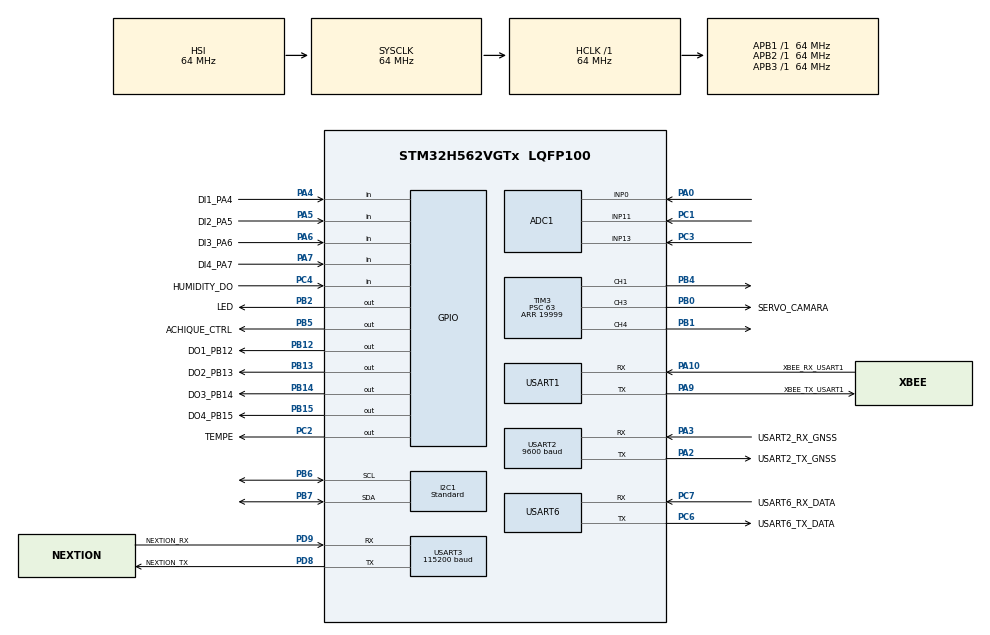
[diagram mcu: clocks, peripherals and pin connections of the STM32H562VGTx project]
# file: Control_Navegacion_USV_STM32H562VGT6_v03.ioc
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ADC1.Channel-0\#ChannelRegularConversion=ADC_CHANNEL_0
ADC1.Channel-1\#ChannelRegularConversion=ADC_CHANNEL_11
ADC1.Channel-2\#ChannelRegularConversion=ADC_CHANNEL_13
ADC1.ContinuousConvMode=ENABLE
ADC1.ConversionDataManagement=ADC_CONVERSIONDATA_DMA_CIRCULAR
ADC1.DMAContinuousRequests=ENABLE
ADC1.MonitoredBy-0\#ChannelRegularConversion=__NULL
ADC1.MonitoredBy-1\#ChannelRegularConversion=__NULL
ADC1.MonitoredBy-2\#ChannelRegularConversion=__NULL
ADC1.NbrOfConversion=3
ADC1.NbrOfConversionFlag=1
ADC1.OffsetNumber-0\#ChannelRegularConversion=ADC_OFFSET_NONE
ADC1.OffsetNumber-1\#ChannelRegularConversion=ADC_OFFSET_NONE
ADC1.OffsetNumber-2\#ChannelRegularConversion=ADC_OFFSET_NONE
ADC1.Rank-0\#ChannelRegularConversion=1
ADC1.Rank-1\#ChannelRegularConversion=2
ADC1.Rank-2\#ChannelRegularConversion=3
ADC1.SamplingTime-0\#ChannelRegularConversion=ADC_SAMPLETIME_47CYCLES_5
ADC1.SamplingTime-1\#ChannelRegularConversion=ADC_SAMPLETIME_47CYCLES_5
ADC1.SamplingTime-2\#ChannelRegularConversion=ADC_SAMPLETIME_47CYCLES_5
ADC1.master=1
BOOTPATH.BootPathName=LEGACY
BOOTPATH.UserSelectedBootPath=LEGACY
CORTEX_M33_NS.Number-Cortex_Memory_Protection_Unit_Region0_OTP_RO_AREAS_Settings=MPU_REGION_NUMBER0
CORTEX_M33_NS.default_mode_Activation=1
CORTEX_M33_NS.userName=CORTEX_M33
GPDMA1.CIRCULARMODE_GPDMACH0=DISABLE
GPDMA1.CIRCULARMODE_GPDMACH1=ENABLE
GPDMA1.DESTDATAWIDTH_GPDMACH1=DMA_DEST_DATAWIDTH_HALFWORD
GPDMA1.DESTINC_GPDMACH0=DMA_DINC_INCREMENTED
GPDMA1.DESTINC_GPDMACH1=DMA_DINC_INCREMENTED
GPDMA1.DESTINC_GPDMACH2=DMA_DINC_INCREMENTED
GPDMA1.IPHANDLE_GPDMACH0-SIMPLEREQUEST_GPDMACH0=__NULL
GPDMA1.IPHANDLE_GPDMACH1-SIMPLEREQUEST_GPDMACH1=__NULL
GPDMA1.IPHANDLE_GPDMACH2-SIMPLEREQUEST_GPDMACH2=__NULL
GPDMA1.PRIORITY_GPDMACH0=DMA_LOW_PRIORITY_MID_WEIGHT
GPDMA1.REQUEST_GPDMACH0=GPDMA1_REQUEST_USART1_RX
GPDMA1.REQUEST_GPDMACH1=GPDMA1_REQUEST_ADC1
GPDMA1.REQUEST_GPDMACH2=GPDMA1_REQUEST_USART2_RX
GPDMA1.SRCDATAWIDTH_GPDMACH1=DMA_SRC_DATAWIDTH_HALFWORD
GPDMA1.SRCINC_GPDMACH1=DMA_SINC_FIXED
I2C1.I2C_Speed_Mode=I2C_Standard
I2C1.Timing=0x30924056
Mcu.Family=STM32H5
Mcu.Name=STM32H562VGTx
Mcu.Package=LQFP100
NVIC.GPDMA1_Channel0_IRQn=true\:0\:0\:false\:false\:true\:false\:true\:true
NVIC.GPDMA1_Channel2_IRQn=true\:0\:0\:false\:false\:true\:true\:true\:true
NVIC.PriorityGroup=NVIC_PRIORITYGROUP_4
NVIC.USART1_IRQn=true\:0\:0\:false\:false\:true\:true\:true\:true
NVIC.USART2_IRQn=true\:0\:0\:false\:false\:true\:true\:true\:true
NVIC.USART3_IRQn=true\:0\:0\:false\:false\:true\:true\:true\:true
NVIC.USART6_IRQn=true\:0\:0\:false\:false\:true\:true\:true\:true
PA0.Signal=ADCx_INP0
PA10.GPIO_Label=XBEE_RX_USART1
PA10.Mode=Asynchronous
PA10.Signal=USART1_RX
PA13(JTMS/SWDIO).Mode=Serial_Wire
PA13(JTMS/SWDIO).Signal=DEBUG_JTMS-SWDIO
PA14(JTCK/SWCLK).Mode=Serial_Wire
PA14(JTCK/SWCLK).Signal=DEBUG_JTCK-SWCLK
PA2.GPIO_Label=USART2_TX_GNSS
PA2.Mode=Asynchronous
PA2.Signal=USART2_TX
PA3.GPIO_Label=USART2_RX_GNSS
PA3.Mode=Asynchronous
PA3.Signal=USART2_RX
PA4.GPIO_Label=DI1_PA4
PA4.GPIO_Mode=GPIO_MODE_INPUT
PA4.GPIO_PuPd=GPIO_NOPULL
PA4.Signal=GPIO_Input
PA5.GPIO_Label=DI2_PA5
PA5.Signal=GPIO_Input
PA6.GPIO_Label=DI3_PA6
PA6.Signal=GPIO_Input
PA7.GPIO_Label=DI4_PA7
PA7.Signal=GPIO_Input
PA9.GPIO_Label=XBEE_TX_USART1
PA9.Mode=Asynchronous
PA9.Signal=USART1_TX
PB0.GPIO_Label=SERVO_CAMARA
PB0.Signal=S_TIM3_CH3
PB1.Signal=S_TIM3_CH4
PB12.GPIO_Label=DO1_PB12
PB12.Signal=GPIO_Output
PB13.GPIO_Label=DO2_PB13
PB13.Signal=GPIO_Output
PB14.GPIO_Label=DO3_PB14
PB14.Signal=GPIO_Output
PB15.GPIO_Label=DO4_PB15
PB15.Signal=GPIO_Output
PB2.GPIO_Label=LED
PB2.Signal=GPIO_Output
PB4(NJTRST).Signal=S_TIM3_CH1
PB5.GPIO_Label=ACHIQUE_CTRL
PB5.GPIO_ModeDefaultOutputPP=GPIO_MODE_OUTPUT_OD
PB5.GPIO_PuPd=GPIO_NOPULL
PB5.PinState=GPIO_PIN_SET
PB5.Signal=GPIO_Output
PB6.GPIO_PuPd=GPIO_PULLUP
PB6.Mode=I2C
PB6.Signal=I2C1_SCL
PB7.GPIO_PuPd=GPIO_PULLUP
PB7.Mode=I2C
PB7.Signal=I2C1_SDA
PC1.Signal=ADCx_INP11
PC2.GPIO_Label=TEMPE
PC2.GPIO_ModeDefaultOutputPP=GPIO_MODE_OUTPUT_OD
PC2.GPIO_PuPd=GPIO_NOPULL
PC2.PinState=GPIO_PIN_SET
PC2.Signal=GPIO_Output
PC3.Signal=ADCx_INP13
PC4.GPIO_Label=HUMIDITY_DO
PC4.Signal=GPIO_Input
PC6.GPIO_Label=USART6_TX_DATA
PC6.Mode=Asynchronous
PC6.Signal=USART6_TX
PC7.GPIO_Label=USART6_RX_DATA
PC7.Mode=Asynchronous
PC7.Signal=USART6_RX
PD8.GPIO_Label=NEXTION_TX
PD8.Mode=Asynchronous
PD8.Signal=USART3_TX
PD9.GPIO_Label=NEXTION_RX
PD9.Mode=Asynchronous
PD9.Signal=USART3_RX
ProjectManager.HeapSize=0x200
ProjectManager.StackSize=0x400
ProjectManager.TargetToolchain=CMake
RCC.ADCFreq_Value=64000000
RCC.AHBFreq_Value=64000000
RCC.APB1Freq_Value=64000000
RCC.APB1TimFreq_Value=64000000
RCC.APB2Freq_Value=64000000
RCC.APB2TimFreq_Value=64000000
RCC.APB3Freq_Value=64000000
RCC.CSI_VALUE=4000000
RCC.CortexFreq_Value=64000000
RCC.EPOD_VALUE=4000000
RCC.HCLKFreq_Value=64000000
RCC.HSE_VALUE=25000000
RCC.HSI48_VALUE=48000000
RCC.HSIDiv=RCC_HSI_DIV1
RCC.HSI_VALUE=64000000
RCC.LSE_VALUE=32768
RCC.LSIRC_VALUE=32000
RCC.SYSCLKFreq_VALUE=64000000
RCC.USBFreq_Value=48000000
RCC.VCOOutputFreq_Value=516000000
SH.ADCx_INP0.0=ADC1_INP0,IN0-Single-Ended
SH.ADCx_INP11.0=ADC1_INP11,IN11-Single-Ended
SH.ADCx_INP13.0=ADC1_INP13,IN13-Single-Ended
SH.S_TIM3_CH1.0=TIM3_CH1,PWM Generation1 CH1
SH.S_TIM3_CH3.0=TIM3_CH3,PWM Generation3 CH3
SH.S_TIM3_CH4.0=TIM3_CH4,PWM Generation4 CH4
TIM3.Channel-PWM\ Generation1\ CH1=TIM_CHANNEL_1
TIM3.Channel-PWM\ Generation3\ CH3=TIM_CHANNEL_3
TIM3.Channel-PWM\ Generation4\ CH4=TIM_CHANNEL_4
TIM3.PeriodNoDither=19999
TIM3.Prescaler=63
TIM3.PulseNoDither_3=1500
USART1.VirtualMode-Asynchronous=VM_ASYNC
USART2.BaudRate=9600
USART2.VirtualMode-Asynchronous=VM_ASYNC
USART3.BaudRate=115200
USART3.VirtualMode-Asynchronous=VM_ASYNC
USART6.VirtualMode=VM_ASYNC
VP_BOOTPATH_VS_BOOTPATH.Mode=BP_Activate
VP_CORTEX_M33_NS_VS_Hclk.Mode=Hclk_Mode
VP_GPDMA1_VS_GPDMACH0.Mode=SIMPLEREQUEST_GPDMACH0
VP_GPDMA1_VS_GPDMACH1.Mode=SIMPLEREQUEST_GPDMACH1
VP_GPDMA1_VS_GPDMACH2.Mode=SIMPLEREQUEST_GPDMACH2
VP_ICACHE_VS_ICACHE.Mode=DirectMappedCache
VP_MEMORYMAP_VS_MEMORYMAP.Mode=CurAppReg
VP_PWR_VS_LPOM.Mode=PowerOptimisation
VP_PWR_VS_SECSignals.Mode=Security/Privilege
VP_TIM3_VS_ClockSourceINT.Mode=Internal
board=custom

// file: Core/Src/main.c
/* USER CODE BEGIN Header */
/**
  ******************************************************************************
  * @file           : main.c
  * @brief          : Main program body
  ******************************************************************************
  * @attention
  *
  * Copyright (c) 2026 STMicroelectronics.
  * All rights reserved.
  *
  * This software is licensed under terms that can be found in the LICENSE file
  * in the root directory of this software component.
  * If no LICENSE file comes with this software, it is provided AS-IS.
  *
  ******************************************************************************
  */
/* USER CODE END Header */
#include "main.h"

/* USER CODE BEGIN Includes */

#include "servos.h"
#include "UARTRX.h"
#include <stdio.h>
#include "imu_bno085_i2c.h"
#include "TELEMETRIA_USV.h"
#include "trama_usv.h"
#include <math.h>
#include "stm32h5xx_hal_gpio.h"
#include "string.h"
#include "stdlib.h"
#include "uart.h"

#include "gps.h"
#include "adc_x.h"
#include "temp_ds18b20.h"
#include "usv_motores.h"
#include "pcb_banco.h"
#include "corriente_lem.h"

#include "stdio.h"
#include "stdlib.h"
#include "stdint.h"

/* USER CODE END Includes */

/* USER CODE BEGIN PD */

/*
 * PRUEBA 12.1:
 * La estacion puede ordenar y aplicar el rango completo -100..+100 %.
 * Se mantienen parada de emergencia y failsafe de enlace a 500 ms.
 */
#define USV_PRUEBA_MOTOR_LIMITE_PCT   100
#define USV_FAILSAFE_TIERRA_MS         500U
/* Tiempo inicial, ajustar con mediciones y perfiles reales XCTU. */
#define XBEE_REPLY_GUARD_MS             60U
/* Rearme RX solamente; no prolongar el failsafe de la propulsion. */
#define XBEE_RX_REARME_SILENCIO_MS     3000U
#define XBEE_RX_REARME_INTERVALO_MS   1000U

/* USER CODE END PD */

ADC_HandleTypeDef hadc1;
DMA_NodeTypeDef Node_GPDMA1_Channel1;
DMA_QListTypeDef List_GPDMA1_Channel1;
DMA_HandleTypeDef handle_GPDMA1_Channel1;

I2C_HandleTypeDef hi2c1;

TIM_HandleTypeDef htim3;

UART_HandleTypeDef huart1;
UART_HandleTypeDef huart2;
UART_HandleTypeDef huart3;
UART_HandleTypeDef huart6;
DMA_HandleTypeDef handle_GPDMA1_Channel0;
DMA_HandleTypeDef handle_GPDMA1_Channel2;

/* USER CODE BEGIN PV */
extern volatile uint32_t usv_xbee_uart1_error_irq;
extern volatile uint32_t usv_xbee_uart1_error_codigo;
extern volatile uint8_t usv_xbee_uart1_recuperar;
char texto[600];

volatile uint8_t imu_ok = 0U;
volatile uint8_t imu_addr = 0U;
volatile uint8_t imu_data_ok = 0U;
/* Diagnostico de arranque inmutable: se muestra en Teleplot a 2 Hz. */
static IMU_Diagnostico imu_diag_arranque;
/* USV 14.9: diagnostico de espera inicial, solo en el arranque. */
#define IMU_149_ESPERA_MS 1500U
static uint32_t imu_149_tick_antes_espera = 0U;
static uint32_t imu_149_tick_inicio = 0U;
static uint32_t imu_149_tick_fin = 0U;
static uint32_t imu_149_espera_real_ms = 0U;
static uint32_t imu_149_init_duracion_ms = 0U;

/* USV 15.0: resultado de sondeo directo unico, previo a IMU_Init.
 * estado: 0=no consultado, 1=STOP sin NACK (ACK probable),
 * 2=NACK observado, 3=espera agotada, 4=error de bus, 5=bus no libre.
 * isr_eventos conserva los bits detectados antes de limpiar banderas.
 */
typedef struct
{
    uint8_t estado;
    uint32_t isr_eventos;
    uint32_t isr_fin;
    uint32_t duracion_ms;
} USV_IMU150_Probe;
static USV_IMU150_Probe imu_150_4a;
static USV_IMU150_Probe imu_150_4b;
static uint32_t imu_150_pe_inicial = 0U;
static uint8_t imu_150_bus_seguro = 0U;

/* USV 15.1: fotografia de registros GPIOB justo antes de consultar la IMU.
 * Se almacenan en RAM; ninguna escritura a GPIOB ni a I2C1.
 */
typedef struct
{
    uint32_t tick_ms;
    uint32_t moder;
    uint32_t otyper;
    uint32_t ospeedr;
    uint32_t pupdr;
    uint32_t afrl;
    uint32_t idr;
} USV_IMU151_GPIO;
static USV_IMU151_GPIO imu_151_gpio;

/* USV 15.2: captura del reloj y TIMINGR efectivo antes de consultar BNO085.
 * Bus estandar 100 kHz nominal: PCLK1=64 MHz, tr=300 ns, tf=100 ns,
 * filtro analogico habilitado, filtro digital 0.
 * Valor calculado estimado; frecuencia fisica depende del bus real.
 */
#define USV_I2C1_TIMING_100KHZ 0x30924056U
static uint32_t imu_152_pclk1_hz = 0U;
static uint32_t imu_152_timingr = 0U;

/* USV 15.4: escaneo exhaustivo de las 112 direcciones I2C de 7 bits
 * que no estan reservadas (0x08 a 0x77 inclusive).
 * El sondeo se hace UNA SOLA VEZ antes de IMU_Init() y se lee desde RAM.
 * Estado: 0=no ejecutado, 1=en curso, 2=completado, 3=interrumpido.
 */
#define USV_I2C_SCAN_MIN_ADDR 0x08U
#define USV_I2C_SCAN_MAX_ADDR 0x77U
#define USV_I2C_SCAN_TOTAL (USV_I2C_SCAN_MAX_ADDR - USV_I2C_SCAN_MIN_ADDR + 1U)
typedef struct
{
    uint8_t estado;
    uint8_t ultimo_addr;
    uint8_t total_ack;
    uint8_t ack_addr[USV_I2C_SCAN_TOTAL];
    uint8_t hal_4a; /* 255=no consultada; 0=HAL_OK */
    uint8_t hal_4b;
    uint16_t consultadas;
    uint16_t hal_error;
    uint16_t hal_timeout;
    uint16_t hal_busy;
    uint16_t error_bus;
    uint32_t err_4a;
    uint32_t err_4b;
    uint32_t pclk1_hz;
    uint32_t timingr;
    uint32_t duracion_ms;
    uint32_t mascara_ack[4]; /* bit N: direccion N (0-127) */
} USV_I2C_ScanResultado;
static USV_I2C_ScanResultado i2c_scan_154;
static uint8_t i2c_scan_154_indice_publicar = 0U;

float imu_roll = 0.0f;
float imu_pitch = 0.0f;
float imu_yaw = 0.0f;

uint32_t imu_last_ms = 0U;
uint32_t teleplot_last_ms = 0U;

/* Heartbeat del lazo principal: incrementa una vez por segundo. */
uint32_t main_alive_last_ms = 0U;
uint32_t main_alive = 0U;

uint32_t temperatura_last_ms = 0U;
uint32_t temperatura_conversion_inicio_ms = 0U;
uint8_t temperatura_conversion_activa = 0U;
float temperatura_c = -100.0f;
uint8_t gps_rmc_ok = 0U;
uint8_t gps_gga_ok = 0U;
uint32_t gnss_rx_eventos = 0U;
uint32_t gnss_ultimo_fix_ms = 0U;
uint32_t servo_test_last_ms = 0U;
uint8_t servo_test_estado = 0U;
float servo_test_angulo = 0.0f;
uint16_t motor_babor_pwm_us = PWM_NEUTRO;
uint16_t motor_estribor_pwm_us = PWM_NEUTRO;
uint8_t motores_pwm_activos = 0U;
uint32_t motores_test_last_ms = 0U;
uint8_t motores_test_estado = 0U;

/* Prueba local de bomba de achique por PB5 / ACHIQUE_CTRL. */
uint32_t bomba_test_last_ms = 0U;
uint8_t bomba_test_estado = 0U;

uint16_t corriente_adc_raw = 0U;
float corriente_voltaje_v = 0.0f;
float corriente_lem_a = 0.0f;

uint16_t bateria_adc_raw = 0U;
float bateria_adc_v = 0.0f;
float bateria_voltaje_v = 0.0f;

/* Ultima trama $PUSVU decodificada desde USART1 / estacion de tierra. */
USV_Comando comando_tierra;
uint8_t comando_tierra_valido = 0U;
static uint8_t xbee_fragmento_rx[600U];
static char xbee_linea[USV_TRAMA_MAXIMA];
static uint16_t xbee_linea_n = 0U;
static uint32_t xbee_tramas_descartadas = 0U;
static uint32_t xbee_rx_eventos = 0U;
static uint32_t xbee_rx_bytes = 0U;
static uint32_t xbee_rx_ultimo_evento_ms = 0U;
static uint32_t xbee_rx_ultimo_rearme_ms = 0U;
static uint32_t xbee_rx_rearmes_ok = 0U;
static uint32_t xbee_rx_rearmes_error = 0U;
static uint32_t xbee_rx_watchdog = 0U;
static uint8_t xbee_reply_pendiente = 0U;
static uint32_t xbee_reply_deadline_ms = 0U;

/* Estado de control remoto para la prueba 12.0. */
int16_t cmd_babor_rx_pct = 0;
int16_t cmd_estribor_rx_pct = 0;
int16_t cmd_camara_rx_deg = 0;
int16_t motor_babor_aplicado_pct = 0;
int16_t motor_estribor_aplicado_pct = 0;
uint8_t parada_rx = 0U;
uint8_t enlace_tierra_ok = 0U;
uint8_t failsafe_tierra_activo = 1U;
uint32_t comando_tierra_ultimo_valido_ms = 0U;
uint32_t pusvu_rx_validas = 0U;

/* Diagnostico desacoplado de la recepcion para no bloquear USART1. */
uint32_t pusvu_diag_last_ms = 0U;
uint8_t pusvu_diag_pendiente = 0U;
uint8_t pusvu_diag_ultimo_valido = 0U;

char teleplot_tx[240];
uint8_t imu_raw[23];

int16_t imu_qi_raw = 0;
int16_t imu_qj_raw = 0;
int16_t imu_qk_raw = 0;
int16_t imu_qr_raw = 0;

volatile uint8_t imu_raw_ok = 0U;
volatile uint8_t imu_raw_channel = 0U;
volatile uint8_t imu_raw_report = 0U;
volatile uint16_t imu_raw_length = 0U;

/*
 * Diagnostico visual del enlace ESTACION -> BOTE.
 *
 * Mientras lleguen tramas por USART1, PB2 conmuta cada 250 ms.
 * Si pasan mas de 400 ms sin recibir nada, se detiene el parpadeo.
 */
uint32_t led_rx_ultimo_evento_ms = 0U;
uint32_t led_rx_ultimo_toggle_ms = 0U;
uint8_t led_rx_activo = 0U;
/* USER CODE END PV */

void SystemClock_Config(void);
static void MPU_Config(void);
static void MX_GPIO_Init(void);
static void MX_GPDMA1_Init(void);
static void MX_ICACHE_Init(void);
static void MX_USART1_UART_Init(void);
static void MX_USART2_UART_Init(void);
static void MX_USART6_UART_Init(void);
static void MX_I2C1_Init(void);
static void MX_TIM3_Init(void);
static void MX_USART3_UART_Init(void);
static void MX_ADC1_Init(void);
/* USER CODE BEGIN PFP */
void procesa_rx(void);
/* USER CODE END PFP */

/* USER CODE BEGIN 0 */
/* DMA+IDLE no representa trama completa: acumular fragmentos hasta CRLF. */
static uint8_t XBee_ExtraerComandos(
        const uint8_t *bytes, uint16_t cantidad,
        USV_Comando *comando, uint8_t *linea_completa)
{
    uint8_t correcto = 0U;
    uint16_t i;
    if ((bytes == NULL) || (comando == NULL) || (linea_completa == NULL))
        return 0U;
    *linea_completa = 0U;
    for (i = 0U; i < cantidad; ++i)
    {
        uint8_t c = bytes[i];
        if (c == (uint8_t)'$')
            xbee_linea_n = 0U;
        else if (xbee_linea_n == 0U)
            continue;
        if (xbee_linea_n >= USV_TRAMA_MAXIMA - 1U)
        {
            ++xbee_tramas_descartadas;
            xbee_linea_n = 0U;
            continue;
        }
        xbee_linea[xbee_linea_n++] = (char)c;
        if (c == (uint8_t)'\n')
        {
            USV_Comando actual;
            xbee_linea[xbee_linea_n] = '\0';
            *linea_completa = 1U;
            if (USV_LeerComando(xbee_linea, &actual) != 0U)
            {
                *comando = actual;
                correcto = 1U;
            }
            else
                ++xbee_tramas_descartadas;
            xbee_linea_n = 0U;
        }
    }
    return correcto;
}

/* Convierte coordenadas decimales entregadas por gps.c al formato NMEA
 * ddmm.mmmm / dddmm.mmmm esperado por Trama Version 3. */
static void USV_GNSS_FormatearCoord(double decimal, uint8_t lon,
                                   char *destino, size_t capacidad)
{
    double abs_coord = (decimal < 0.0) ? -decimal : decimal;
    unsigned long grados = (unsigned long)abs_coord;
    double minutos = (abs_coord - (double)grados) * 60.0;
    if (minutos >= 59.99995)
    {
        ++grados;
        minutos = 0.0;
    }
    if (lon != 0U)
        (void)snprintf(destino, capacidad, "%03lu%07.4f", grados, minutos);
    else
        (void)snprintf(destino, capacidad, "%02lu%07.4f", grados, minutos);
}

/* Sincroniza la estructura de telemetria con las mediciones GNSS decodificadas.
 * NO cambia la velocidad y el rumbo si aun no hay solucion valida. */
static void USV_ActualizarTelemetriaGNSS(uint8_t fix_valido)
{
    char utc[USV_TAMANO_UTC];
    char lat_nmea[USV_TAMANO_COORDENADA];
    char lon_nmea[USV_TAMANO_COORDENADA];
    uint16_t hdop10, vel10, rumbo10;
    int32_t alt10;
    uint8_t calidad, sats;
    uint8_t hh = (uint8_t)(((int16_t)hor_gps + 5 + 24) % 24);

    if (fix_valido == 0U)
    {
        TELEMETRIA1.datos.calidad_gps = 0U;
        TELEMETRIA1.datos.satelites = 0U;
        return;
    }
    /* gps.c ofrece hora LOCAL de Colombia; convertir de nuevo a UTC. */
    (void)snprintf(utc, sizeof(utc), "%02u%02u%02u.00",
                   (unsigned)hh, (unsigned)min_gps, (unsigned)seg_gps);
    USV_GNSS_FormatearCoord(latitud, 0U, lat_nmea, sizeof(lat_nmea));
    USV_GNSS_FormatearCoord(longitud, 1U, lon_nmea, sizeof(lon_nmea));
    calidad = (uint8_t)((gps_modo >= 1 && gps_modo <= 8) ?
                         gps_modo : 1);
    sats = (uint8_t)((gps_satelites >= 0 && gps_satelites <= 24) ?
                     gps_satelites : 0);
    hdop10 = (uint16_t)((gps_hor_dilu >= 0.5f &&
                         gps_hor_dilu <= 50.0f) ?
                        (gps_hor_dilu * 10.0f + 0.5f) : 500.0f);
    alt10 = (int32_t)((gps_altura >= -10.0f &&
                       gps_altura <= 9999.0f) ?
                       (gps_altura * 10.0f) : 0.0f);
    /* La Trama V3 etiqueta velocidad con N: transmitir NUDOS, no km/h. */
    vel10 = (uint16_t)((gps_vel_nudos >= 0.0f &&
                        gps_vel_nudos <= 30.0f) ?
                        (gps_vel_nudos * 10.0f + 0.5f) : 0.0f);
    rumbo10 = (uint16_t)((gps_rumbo >= 0.0f &&
                          gps_rumbo < 360.0f) ?
                         (gps_rumbo * 10.0f + 0.5f) : 0.0f);
    TELEMETRIA_USV_GPS(&TELEMETRIA1, utc, lat_nmea,
                       (latitud < 0.0) ? 'S' : 'N',
                       lon_nmea, (longitud < 0.0) ? 'W' : 'E',
                       calidad, sats, hdop10, alt10, vel10, rumbo10);
}

/*
 * Convierte los angulos reales del BNO085 al formato exigido por $PUSVD.
 *
 * - yaw:   0.0 ... 359.9 grados, almacenado x10.
 * - pitch: -90.0 ... +90.0 grados, almacenado x10.
 * - roll:  -90.0 ... +90.0 grados, almacenado x10.
 *
 * El BNO085 puede entregar roll fuera de +/-90 dependiendo de la orientacion.
 * La Trama Version 3 no admite ese rango, por eso se satura antes de enviarlo.
 */
static void USV_ActualizarTelemetriaIMU(
        float roll,
        float pitch,
        float yaw)
{
    int32_t yaw_x10;
    int32_t pitch_x10;
    int32_t roll_x10;

    while (yaw < 0.0f)
    {
        yaw += 360.0f;
    }

    while (yaw >= 360.0f)
    {
        yaw -= 360.0f;
    }

    if (pitch < -90.0f)
    {
        pitch = -90.0f;
    }
    else if (pitch > 90.0f)
    {
        pitch = 90.0f;
    }

    if (roll < -90.0f)
    {
        roll = -90.0f;
    }
    else if (roll > 90.0f)
    {
        roll = 90.0f;
    }

    yaw_x10 =
        (int32_t)((yaw * 10.0f) + 0.5f);

    pitch_x10 =
        (int32_t)((pitch >= 0.0f) ?
            ((pitch * 10.0f) + 0.5f) :
            ((pitch * 10.0f) - 0.5f));

    roll_x10 =
        (int32_t)((roll >= 0.0f) ?
            ((roll * 10.0f) + 0.5f) :
            ((roll * 10.0f) - 0.5f));

    if (yaw_x10 > 3599)
    {
        yaw_x10 = 3599;
    }

    TELEMETRIA_USV_IMU(
        &TELEMETRIA1,
        (uint16_t)yaw_x10,
        (int16_t)pitch_x10,
        (int16_t)roll_x10);
}

/*
 * Reconstruye el porcentaje con signo desde la estructura decodificada.
 * Positivo = avante, negativo = reversa.
 */
static int16_t USV_ComandoMotorFirmado(
        uint16_t potencia,
        uint8_t avante,
        uint8_t atras)
{
    if ((avante != 0U) && (atras == 0U))
    {
        return (int16_t)potencia;
    }

    if ((avante == 0U) && (atras != 0U))
    {
        return -(int16_t)potencia;
    }

    return 0;
}

/*
 * Limita el porcentaje de prueba y lo convierte a PWM ESC:
 * -100 % = 1000 us, 0 % = 1500 us, +100 % = 2000 us.
 * Para la prueba 12.1 se habilita el rango completo +/-100 %.
 */
static uint16_t USV_MotorPctAPwmPrueba(
        int16_t porcentaje,
        int16_t *porcentaje_aplicado)
{
    int16_t limitado = porcentaje;
    int32_t pwm;

    if (limitado > USV_PRUEBA_MOTOR_LIMITE_PCT)
    {
        limitado = USV_PRUEBA_MOTOR_LIMITE_PCT;
    }
    else if (limitado < -USV_PRUEBA_MOTOR_LIMITE_PCT)
    {
        limitado = -USV_PRUEBA_MOTOR_LIMITE_PCT;
    }

    if (porcentaje_aplicado != NULL)
    {
        *porcentaje_aplicado = limitado;
    }

    pwm = (int32_t)PWM_NEUTRO + ((int32_t)limitado * 5);

    if (pwm > PWM_MAX_ADELANTE)
    {
        pwm = PWM_MAX_ADELANTE;
    }
    else if (pwm < PWM_MAX_REVERSA)
    {
        pwm = PWM_MAX_REVERSA;
    }

    return (uint16_t)pwm;
}

/* void procesa_rx()
 {
  char procesa[100];
    char texto[100];
if (strstr(UARTRX1.trama_rx,"$PUSVU"))
	    {
	        strcpy(procesa, strtok(UARTRX1.trama_rx, "$"));  //inicia captura de tokens desde el =
	        strcpy(procesa, strtok(0, ","));  //captura hasta el /
strcpy(procesa, strtok(0, ","));  //captura hasta el /
strcpy(procesa, strtok(0, ","));  //captura hasta el /
strcpy(procesa, strtok(0, ","));  //captura hasta el /
strcpy(procesa, strtok(0, ","));  //captura hasta el /
strcpy(procesa, strtok(0, ","));  //captura hasta el /
 float serv=atof(procesa); // con signo
 sprintf(texto, "Servo= %.2f\r\n\r\n", serv);
 uartx_write_text(&huart1, texto);

 }
  } */
/* USV 15.0: prueba I2C de direccion (NBYTES=0) sin usar HAL en paralelo.
 * Solo puede ejecutarse con HAL READY y el bus inactivo, en arranque.
 * No se modifica la configuracion TIMINGR ni los GPIO.
 * Limite de 15 ms por direccion. No reintenta ni se invoca en while(1).
 */
static uint8_t USV_IMU150_ProbarDireccion(uint8_t direccion7,
                                         USV_IMU150_Probe *resultado)
{
    uint32_t tick_inicio;
    uint32_t isr;
    uint32_t cr2_previo;

    if (resultado == NULL)
    {
        return 0U;
    }
    memset(resultado, 0, sizeof(*resultado));
    if ((HAL_I2C_GetState(&hi2c1) != HAL_I2C_STATE_READY) ||
        ((hi2c1.Instance->CR1 & I2C_CR1_PE) == 0U) ||
        ((hi2c1.Instance->ISR & I2C_ISR_BUSY) != 0U))
    {
        resultado->estado = 5U;
        resultado->isr_fin = hi2c1.Instance->ISR;
        return 0U;
    }

    cr2_previo = hi2c1.Instance->CR2;
    /* Borrar exclusivamente banderas residuales de la prueba anterior. */
    hi2c1.Instance->ICR = I2C_ICR_NACKCF | I2C_ICR_STOPCF |
                          I2C_ICR_BERRCF | I2C_ICR_ARLOCF;
    tick_inicio = HAL_GetTick();
    /* Direccion SADD de 7 bits desplazada; AUTOEND con NBYTES=0. */
    hi2c1.Instance->CR2 = ((uint32_t)direccion7 << 1U) |
                          I2C_CR2_AUTOEND | I2C_CR2_START;

    do
    {
        isr = hi2c1.Instance->ISR;
        resultado->isr_eventos |= isr & (I2C_ISR_NACKF |
            I2C_ISR_STOPF | I2C_ISR_BERR | I2C_ISR_ARLO);
        if ((isr & (I2C_ISR_BERR | I2C_ISR_ARLO)) != 0U)
        {
            resultado->estado = 4U;
            break;
        }
        if ((isr & I2C_ISR_STOPF) != 0U)
        {
            resultado->estado =
                ((resultado->isr_eventos & I2C_ISR_NACKF) != 0U) ? 2U : 1U;
            break;
        }
    } while ((uint32_t)(HAL_GetTick() - tick_inicio) < 15U);

    if (resultado->estado == 0U)
    {
        resultado->estado = 3U;
    }
    resultado->duracion_ms = HAL_GetTick() - tick_inicio;
    resultado->isr_fin = hi2c1.Instance->ISR;

    if ((resultado->isr_fin & I2C_ISR_BUSY) != 0U)
    {
        /* No escribir CR2 ni iniciar nuevas transacciones con BUSY activo. */
        resultado->estado = 5U;
        return 0U;
    }
    hi2c1.Instance->ICR = I2C_ICR_NACKCF | I2C_ICR_STOPCF |
                          I2C_ICR_BERRCF | I2C_ICR_ARLOCF;
    hi2c1.Instance->CR2 = cr2_previo;
    /* Solo encadenar transacciones si se observo STOP completo. */
    return (resultado->estado == 1U || resultado->estado == 2U) ? 1U : 0U;
}

/* USV 15.4: escaneo de direcciones, sin escritura de datos.
 * HAL_I2C_IsDeviceReady emite la direccion 7-bit desplazada.
 * Cada direccion se consulta una sola vez, con limite de 10 ms.
 * Si hay bloqueo/BUSY/error de bus, se declara incompleto.
 */
static void USV_I2C_ScanCompleto(void)
{
    uint8_t addr;
    uint32_t inicio = HAL_GetTick();
    HAL_StatusTypeDef estado_hal;
    uint32_t error;

    memset(&i2c_scan_154, 0, sizeof(i2c_scan_154));
    i2c_scan_154.hal_4a = 255U;
    i2c_scan_154.hal_4b = 255U;
    i2c_scan_154.pclk1_hz = HAL_RCC_GetPCLK1Freq();
    i2c_scan_154.timingr = hi2c1.Instance->TIMINGR;

    if ((HAL_I2C_GetState(&hi2c1) != HAL_I2C_STATE_READY) ||
        ((hi2c1.Instance->CR1 & I2C_CR1_PE) == 0U) ||
        ((hi2c1.Instance->ISR & I2C_ISR_BUSY) != 0U))
    {
        i2c_scan_154.estado = 3U;
        i2c_scan_154.hal_busy = 1U;
        i2c_scan_154.duracion_ms = HAL_GetTick() - inicio;
        return;
    }

    i2c_scan_154.estado = 1U;
    for (addr = USV_I2C_SCAN_MIN_ADDR; addr <= USV_I2C_SCAN_MAX_ADDR; ++addr)
    {
        estado_hal = HAL_I2C_IsDeviceReady(
            &hi2c1, (uint16_t)((uint16_t)addr << 1U), 1U, 10U);
        error = HAL_I2C_GetError(&hi2c1);

        i2c_scan_154.consultadas++;
        i2c_scan_154.ultimo_addr = addr;

        if (addr == 0x4AU)
        {
            i2c_scan_154.hal_4a = (uint8_t)estado_hal;
            i2c_scan_154.err_4a = error;
        }
        if (addr == 0x4BU)
        {
            i2c_scan_154.hal_4b = (uint8_t)estado_hal;
            i2c_scan_154.err_4b = error;
        }

        if (estado_hal == HAL_OK)
        {
            i2c_scan_154.ack_addr[i2c_scan_154.total_ack++] = addr;
            i2c_scan_154.mascara_ack[addr / 32U] |=
                (1UL << (addr % 32U));
        }
        else if (estado_hal == HAL_ERROR)
        {
            i2c_scan_154.hal_error++;
        }
        else if (estado_hal == HAL_TIMEOUT)
        {
            i2c_scan_154.hal_timeout++;
            i2c_scan_154.estado = 3U;
            break;
        }
        else /* HAL_BUSY */
        {
            i2c_scan_154.hal_busy++;
            i2c_scan_154.estado = 3U;
            break;
        }

        if ((error & (HAL_I2C_ERROR_BERR | HAL_I2C_ERROR_ARLO)) != 0U)
        {
            i2c_scan_154.error_bus++;
            i2c_scan_154.estado = 3U;
            break;
        }
        if ((hi2c1.Instance->ISR & I2C_ISR_BUSY) != 0U)
        {
            i2c_scan_154.hal_busy++;
            i2c_scan_154.estado = 3U;
            break;
        }
    }

    if (i2c_scan_154.consultadas == USV_I2C_SCAN_TOTAL &&
        i2c_scan_154.estado == 1U)
    {
        i2c_scan_154.estado = 2U;
    }
    i2c_scan_154.duracion_ms = HAL_GetTick() - inicio;
}

/* USER CODE END 0 */

int main(void)
{

  /* MCU Configuration--------------------------------------------------------*/

  /* MPU Configuration--------------------------------------------------------*/
  MPU_Config();

  /* Reset of all peripherals, Initializes the Flash interface and the Systick. */
  HAL_Init();

  /* Configure the system clock */
  SystemClock_Config();

  /* Initialize all configured peripherals */
  MX_GPIO_Init();
  MX_GPDMA1_Init();
  MX_ICACHE_Init();
  MX_USART1_UART_Init();
  MX_USART2_UART_Init();
  MX_USART6_UART_Init();
  MX_I2C1_Init();
  MX_TIM3_Init();
  MX_USART3_UART_Init();
  MX_ADC1_Init();
  /* USER CODE BEGIN 2 */

/*
 * AUTOPRUEBA PB2:
 * Al arrancar, el LED cambia de estado durante 300 ms y vuelve al estado inicial.
 * Si este destello no se ve, el problema esta en PB2/LED y no en la UART.
 */
HAL_GPIO_WritePin(
    LED_RX_TIERRA_GPIO_Port,
    LED_RX_TIERRA_Pin,
    GPIO_PIN_SET);
HAL_Delay(300U);

HAL_GPIO_WritePin(
    LED_RX_TIERRA_GPIO_Port,
    LED_RX_TIERRA_Pin,
    GPIO_PIN_RESET);
HAL_Delay(300U);

// Inicializa la señal PWM en el pin PB0 (SERVO_CAMARA)
#if !PCB_BANCO_ACTIVO
SERVO_init(&SERVO1);
SERVO_ANG(&SERVO1, 0.0f);
#else
/* En banco, no generar PWM del servo hasta recibir orden manual. */
servo_test_angulo = 0.0f;
#endif // Posiciona inicialmente la cámara al centro (0°)

/*
 * PRUEBA LOCAL MOTORES 6.2:
 * Inicia únicamente las salidas PWM de propulsion en NEUTRO.
 * No se ejecuta USV_Motor_Calibrar() y no se ordena movimiento.
 * Babor    = PB4 / TIM3_CH1
 * Estribor = PB1 / TIM3_CH4
 */
if ((HAL_TIM_PWM_Start(&htim3, TIM_CHANNEL_1) == HAL_OK) &&
    (HAL_TIM_PWM_Start(&htim3, TIM_CHANNEL_4) == HAL_OK))
{
    USV_Motor_Set(&htim3, TIM_CHANNEL_1, PWM_NEUTRO);
    USV_Motor_Set(&htim3, TIM_CHANNEL_4, PWM_NEUTRO);

    motor_babor_pwm_us = PWM_NEUTRO;
    motor_estribor_pwm_us = PWM_NEUTRO;
    motores_pwm_activos = 1U;
}

/*
 * La prueba de bomba inicia con el rele desenergizado.
 * PB5 es open-drain y el rele es activo en LOW:
 * SET = alta impedancia = OFF.
 * RESET = 0 V = ON.
 */
HAL_GPIO_WritePin(
    ACHIQUE_CTRL_GPIO_Port,
    ACHIQUE_CTRL_Pin,
    GPIO_PIN_SET);
bomba_test_estado = 0U;
bomba_test_last_ms = HAL_GetTick();

uartx_write_text(&huart6, "INICIANDO\r\n");
#if PCB_BANCO_ACTIVO
PCB_Banco_Iniciar();
#endif
//uartRX_it_idle_dma_init(&UARTRX1);
uartRX_it_idle_dma_init(&GPS_UARTRX);   // USART1 / estacion de tierra
xbee_rx_ultimo_evento_ms = HAL_GetTick();
xbee_rx_ultimo_rearme_ms = HAL_GetTick();
uartRX_it_idle_dma_init(&GNSS_UARTRX);   // USART2 / GPS L76K

// Inicializa la telemetria oficial $PUSVD por USART1 / XBee
TELEMETRIA_USV_init(&TELEMETRIA1);

/* USV 14.9: espera adicional fija para probar estabilidad de arranque.
 * Las dos pausas existentes de 300 ms del LED permanecen intactas.
 * No se modifican I2C1, XBee, PWM, SHTP ni el failsafe.
 * Atencion: esta espera bloquea el avance de la secuencia de arranque.
 */
imu_149_tick_antes_espera = HAL_GetTick();
HAL_Delay(IMU_149_ESPERA_MS);
imu_149_tick_inicio = HAL_GetTick();
imu_149_espera_real_ms = imu_149_tick_inicio - imu_149_tick_antes_espera;

/* USV 15.4: escanear antes de hacer comprobaciones del BNO085.
 * No reconfigura PB6/PB7 ni modifica el protocolo de los subsistemas.
 */
USV_I2C_ScanCompleto();

/* USV 15.2: capturar reloj PCLK1 y TIMINGR cargado en I2C1. */
imu_152_pclk1_hz = HAL_RCC_GetPCLK1Freq();
imu_152_timingr = hi2c1.Instance->TIMINGR;

/* USV 15.1: leer GPIOB justo antes de la primera consulta I2C.
 * PB6 = SCL y PB7 = SDA. Esta lectura no cambia el hardware.
 */
imu_151_gpio.tick_ms = HAL_GetTick();
imu_151_gpio.moder = GPIOB->MODER;
imu_151_gpio.otyper = GPIOB->OTYPER;
imu_151_gpio.ospeedr = GPIOB->OSPEEDR;
imu_151_gpio.pupdr = GPIOB->PUPDR;
imu_151_gpio.afrl = GPIOB->AFR[0];
imu_151_gpio.idr = GPIOB->IDR;

/* USV 15.0: dos sondeos directos antes de HAL_I2C_IsDeviceReady.
 * Si 0x4A no libera bus, omitir 0x4B y conservar el diagnostico.
 */
imu_150_pe_inicial = (hi2c1.Instance->CR1 & I2C_CR1_PE) != 0U;
if (USV_IMU150_ProbarDireccion(0x4AU, &imu_150_4a) != 0U)
{
    imu_150_bus_seguro = USV_IMU150_ProbarDireccion(0x4BU, &imu_150_4b);
}

// Evitar HAL si algun sondeo no concluyo con STOP completo.
if ((imu_150_bus_seguro != 0U) &&
    ((hi2c1.Instance->ISR & I2C_ISR_BUSY) == 0U))
{
    imu_ok = IMU_Init();
}
else
{
    imu_ok = 0U;
}
imu_149_tick_fin = HAL_GetTick();
imu_149_init_duracion_ms = imu_149_tick_fin - imu_149_tick_inicio;
imu_addr = IMU_GetAddress7bit();
IMU_GetDiagnostico(&imu_diag_arranque);

// Inicializa DS18B20 / 1-Wire en PC2 (TEMPE)
TEMPE_Init();

/*
 * Inicia ADC1 por DMA usando la libreria adc_x.
 * CubeMX tiene 3 conversiones:
 * [0] PA0, [1] PC1, [2] PC3 (humedad).
 * PC2 ya no pertenece al ADC: se usa para DS18B20 / 1-Wire.
 * Se pasa 3 de forma explicita para no modificar la libreria adc_x.
 */
ADC_Read_DMA(&hadc1, 3U, adc1_codigo);

  /* USER CODE END 2 */

  /* Infinite loop */
  /* USER CODE BEGIN WHILE */
  while (1)
  {
#if PCB_BANCO_ACTIVO
    PCB_Banco_Tarea();
#endif
    /*
     * Heartbeat de diagnostico.
     * Si main_alive sigue aumentando, el while(1) continua ejecutandose.
     */
    if ((uint32_t)(HAL_GetTick() - main_alive_last_ms) >= 1000U)
    {
        main_alive_last_ms = HAL_GetTick();
        main_alive++;
    }

    /* Lectura IMU cada 50 ms */
    if ((HAL_GetTick() - imu_last_ms) >= 50U)
    {
        imu_last_ms = HAL_GetTick();

        if (IMU_ReadEuler(
                &imu_roll,
                &imu_pitch,
                &imu_yaw) != 0U)
        {
            imu_data_ok = 1U;

            USV_ActualizarTelemetriaIMU(
                imu_roll,
                imu_pitch,
                imu_yaw);
        }
    }

    /*
     * PRUEBA 12.0:
     * Servo y motores ya no se fuerzan aqui a una posicion fija.
     * Las salidas se actualizan exclusivamente cuando llega una $PUSVU
     * valida y por el failsafe de perdida de enlace definido mas abajo.
     */

    /* La bomba arranca desenergizada y solo cambia por una orden
     * PUSVU valida o cuando el failsafe corta el enlace. */

    /*
     * TEMPERATURA DS18B20 NO BLOQUEANTE:
     *
     * La conversion se inicia cada 2 s y el main continua ejecutandose.
     * Transcurridos 750 ms se lee el scratchpad. De esta forma USART1,
     * Teleplot, IMU y el resto de tareas siguen siendo atendidos durante
     * el tiempo de conversion del sensor.
     */
    {
        uint32_t ahora_temp = HAL_GetTick();

        if (temperatura_conversion_activa == 0U)
        {
            if ((uint32_t)(ahora_temp - temperatura_last_ms) >= 2000U)
            {
                temperatura_last_ms = ahora_temp;

                if (TEMPE_StartConversion() != 0U)
                {
                    temperatura_conversion_inicio_ms = ahora_temp;
                    temperatura_conversion_activa = 1U;
                }
                else
                {
                    temperatura_c = -100.0f;
                }
            }
        }
        else if ((uint32_t)(ahora_temp - temperatura_conversion_inicio_ms) >= 750U)
        {
            temperatura_c = TEMPE_ReadResult();
            temperatura_conversion_activa = 0U;
            /* No inventar temperatura cuando el DS18B20 no responde.
             * La version 3 admite -10.0..85.0 C. */
            if ((temperatura_c >= -10.0f) && (temperatura_c <= 85.0f))
            {
                TELEMETRIA1.datos.temperatura_x10 =
                    (int16_t)((temperatura_c * 10.0f) +
                        ((temperatura_c >= 0.0f) ? 0.5f : -0.5f));
            }
        }
    }

    /*
     * TELEPLOT SEGURO 11.4:
     * Se limita a 2 Hz para reducir la carga de USART6 durante la prueba
     * continua de comunicacion con la estacion de tierra.
     */
    if ((HAL_GetTick() - teleplot_last_ms) >= 500U)
    {
        float humedad_pct;
        int len;

        teleplot_last_ms = HAL_GetTick();

        /*
         * SENSOR DE CORRIENTE LEM HASS 200-S:
         * PA0 = ADC1_INP0 = adc1_codigo[0].
         * Se conserva intacta la libreria corriente_lem.
         */
        corriente_adc_raw = adc1_codigo[0];
        corriente_voltaje_v =
            ((float)corriente_adc_raw / STM32_ADC_MAX_CODES) *
            STM32_ADC_VREF;
        corriente_lem_a =
            LEM_HASS200_ObtenerCorriente(corriente_adc_raw);

        /*
         * SENSOR DE VOLTAJE DE BATERIA:
         * PC1 = ADC1_INP11 = adc1_codigo[1].
         * Divisor nominal: R1=20 kOhm, R2=4.7 kOhm.
         * Factor nominal = (20k + 4.7k) / 4.7k = 5.255.
         *
         * Para esta primera prueba se usa el factor nominal y se compara
         * contra el multimetro antes de aplicar cualquier calibracion.
         */
        bateria_adc_raw = adc1_codigo[1];
        bateria_adc_v =
            ((float)bateria_adc_raw / 4095.0f) * 3.3f;
        bateria_voltaje_v =
            bateria_adc_v * 5.255f;

        /*
         * INTEGRACION $PUSVD 9.1:
         * Convierte las mediciones electricas al formato x10 de la trama.
         * Se preservan temperatura e inundacion hasta integrarlas en su etapa.
         */
        {
            float bateria_tx_v = bateria_voltaje_v;
            float corriente_tx_a = corriente_lem_a;
            uint16_t bateria_tx_x10;
            uint16_t corriente_tx_x10;

            if (bateria_tx_v < 0.0f)
            {
                bateria_tx_v = 0.0f;
            }
            else if (bateria_tx_v > 14.0f)
            {
                bateria_tx_v = 14.0f;
            }

            if (corriente_tx_a < 0.0f)
            {
                corriente_tx_a = 0.0f;
            }
            else if (corriente_tx_a > 100.0f)
            {
                corriente_tx_a = 100.0f;
            }

            bateria_tx_x10 =
                (uint16_t)((bateria_tx_v * 10.0f) + 0.5f);

            corriente_tx_x10 =
                (uint16_t)((corriente_tx_a * 10.0f) + 0.5f);

            TELEMETRIA_USV_SENSORES(
                &TELEMETRIA1,
                TELEMETRIA1.datos.temperatura_x10,
                TELEMETRIA1.datos.inundacion,
                bateria_tx_x10,
                corriente_tx_x10);
        }

        humedad_pct =
            ((4095.0f - (float)adc1_codigo[2]) * 100.0f) /
            (4095.0f - 1466.0f);

        if (humedad_pct < 0.0f)
        {
            humedad_pct = 0.0f;
        }
        else if (humedad_pct > 100.0f)
        {
            humedad_pct = 100.0f;
        }

        /* Bloque 1: sensores basicos y servo. */
        len = snprintf(
            texto,
            sizeof(texto),
            ">humedad_adc:%u\r\n"
            ">humedad_pct:%.1f\r\n"
            ">temperatura_c:%.2f\r\n"
            ">servo_angulo:%.1f\r\n"
            ">servo_pwm_us:%lu\r\n"
            ">cmd_babor_rx_pct:%d\r\n"
            ">cmd_estribor_rx_pct:%d\r\n"
            ">cmd_camara_rx_deg:%d\r\n"
            ">motor_babor_aplicado_pct:%d\r\n"
            ">motor_estribor_aplicado_pct:%d\r\n"
            ">motores_pwm_activos:%u\r\n"
            ">motor_babor_pwm_us:%u\r\n"
            ">motor_estribor_pwm_us:%u\r\n"
            ">parada_rx:%u\r\n"
            ">enlace_tierra_ok:%u\r\n"
            ">failsafe_tierra:%u\r\n"
            ">pusvu_rx_validas:%lu\r\n"
            ">bomba_achique:%u\r\n"
            ">main_alive:%lu\r\n",
            (unsigned int)adc1_codigo[2],
            humedad_pct,
            temperatura_c,
            servo_test_angulo,
            (unsigned long)TIM3->CCR3,
            (int)cmd_babor_rx_pct,
            (int)cmd_estribor_rx_pct,
            (int)cmd_camara_rx_deg,
            (int)motor_babor_aplicado_pct,
            (int)motor_estribor_aplicado_pct,
            (unsigned int)motores_pwm_activos,
            (unsigned int)motor_babor_pwm_us,
            (unsigned int)motor_estribor_pwm_us,
            (unsigned int)parada_rx,
            (unsigned int)enlace_tierra_ok,
            (unsigned int)failsafe_tierra_activo,
            (unsigned long)pusvu_rx_validas,
            (unsigned int)bomba_test_estado,
            (unsigned long)main_alive);

        if ((len > 0) && ((size_t)len < sizeof(texto)))
        {
            uartx_write_text(&huart6, texto);
        }

        /* Bloque 2: diagnostico IMU. */
        len = snprintf(
            texto,
            sizeof(texto),
            ">imu_ok:%u\r\n"
            ">imu_addr:%u\r\n"
            ">imu_data_ok:%u\r\n"
            ">imu_i2c_pines:%u\r\n"
            ">imu_i2c_error_hal:%lu\r\n"
            ">imu_diag_etapa:%u\r\n"
            ">imu_probe_4a_hal:%u\r\n"
            ">imu_probe_4a_error:%lu\r\n"
            ">imu_probe_4b_hal:%u\r\n"
            ">imu_probe_4b_error:%lu\r\n"
            ">imu_diag_error_etapa:%lu\r\n"
            ">roll:%.2f\r\n"
            ">pitch:%.2f\r\n"
            ">yaw:%.2f\r\n",
            (unsigned int)imu_ok,
            (unsigned int)imu_addr,
            (unsigned int)imu_data_ok,
            (unsigned int)((GPIOB->IDR >> 6U) & 0x3U),
            (unsigned long)HAL_I2C_GetError(&hi2c1),
            (unsigned int)imu_diag_arranque.etapa,
            (unsigned int)imu_diag_arranque.estado_4a,
            (unsigned long)imu_diag_arranque.error_4a,
            (unsigned int)imu_diag_arranque.estado_4b,
            (unsigned long)imu_diag_arranque.error_4b,
            (unsigned long)imu_diag_arranque.error_etapa,
            imu_roll,
            imu_pitch,
            imu_yaw);

        if ((len > 0) && ((size_t)len < sizeof(texto)))
        {
            uartx_write_text(&huart6, texto);
        }

        /* USV 14.7: instantaneas I2C1 de arranque; lectura de RAM a 2 Hz. */
        len = snprintf(
            texto, sizeof(texto),
            ">imu_i2c_estado:%lu\r\n"
            ">imu_i2c_modo:%lu\r\n"
            ">imu_i2c_isr:%lu\r\n"
            ">imu_i2c_busy:%u\r\n"
            ">imu_i2c_nack:%u\r\n"
            ">imu_i2c_berr:%u\r\n"
            ">imu_i2c_arbitration:%u\r\n"
            ">imu_i2c_isr_inicial:%lu\r\n"
            ">imu_i2c_isr_4a:%lu\r\n"
            ">imu_i2c_isr_4b:%lu\r\n",
            (unsigned long)imu_diag_arranque.estado_i2c,
            (unsigned long)imu_diag_arranque.modo_i2c,
            (unsigned long)imu_diag_arranque.isr_final,
            (unsigned int)((imu_diag_arranque.isr_final & I2C_ISR_BUSY) != 0U),
            (unsigned int)((imu_diag_arranque.isr_final & I2C_ISR_NACKF) != 0U),
            (unsigned int)((imu_diag_arranque.isr_final & I2C_ISR_BERR) != 0U),
            (unsigned int)((imu_diag_arranque.isr_final & I2C_ISR_ARLO) != 0U),
            (unsigned long)imu_diag_arranque.isr_inicial,
            (unsigned long)imu_diag_arranque.isr_4a,
            (unsigned long)imu_diag_arranque.isr_4b);
        if ((len > 0) && ((size_t)len < sizeof(texto)))
        {
            uartx_write_text(&huart6, texto);
        }

        /* USV 14.8: traza de pruebas HAL 0x4A y 0x4B; solo RAM. */
        len = snprintf(
            texto, sizeof(texto),
            ">imu_148_cr1:%lu\r\n"
            ">imu_148_cr2:%lu\r\n"
            ">imu_148_timingr:%lu\r\n"
            ">imu_148_pe:%u\r\n"
            ">imu_148_addrmode:%lu\r\n"
            ">imu_148_4a_s1:%u\r\n"
            ">imu_148_4a_s2:%u\r\n"
            ">imu_148_4a_s3:%u\r\n"
            ">imu_148_4b_s1:%u\r\n"
            ">imu_148_4b_s2:%u\r\n"
            ">imu_148_4b_s3:%u\r\n",
            (unsigned long)imu_diag_arranque.cr1_inicio,
            (unsigned long)imu_diag_arranque.cr2_inicio,
            (unsigned long)imu_diag_arranque.timingr_inicio,
            (unsigned int)((imu_diag_arranque.cr1_inicio & I2C_CR1_PE) != 0U),
            (unsigned long)imu_diag_arranque.addressing_mode,
            (unsigned int)imu_diag_arranque.probe_hal[0][0],
            (unsigned int)imu_diag_arranque.probe_hal[0][1],
            (unsigned int)imu_diag_arranque.probe_hal[0][2],
            (unsigned int)imu_diag_arranque.probe_hal[1][0],
            (unsigned int)imu_diag_arranque.probe_hal[1][1],
            (unsigned int)imu_diag_arranque.probe_hal[1][2]);
        if ((len > 0) && ((size_t)len < sizeof(texto)))
        {
            uartx_write_text(&huart6, texto);
        }
        len = snprintf(
            texto, sizeof(texto),
            ">imu_148_4a_e1:%lu\r\n"
            ">imu_148_4a_e2:%lu\r\n"
            ">imu_148_4a_e3:%lu\r\n"
            ">imu_148_4b_e1:%lu\r\n"
            ">imu_148_4b_e2:%lu\r\n"
            ">imu_148_4b_e3:%lu\r\n"
            ">imu_148_4a_t1:%lu\r\n"
            ">imu_148_4a_t2:%lu\r\n"
            ">imu_148_4a_t3:%lu\r\n"
            ">imu_148_4b_t1:%lu\r\n"
            ">imu_148_4b_t2:%lu\r\n"
            ">imu_148_4b_t3:%lu\r\n",
            (unsigned long)imu_diag_arranque.probe_error[0][0],
            (unsigned long)imu_diag_arranque.probe_error[0][1],
            (unsigned long)imu_diag_arranque.probe_error[0][2],
            (unsigned long)imu_diag_arranque.probe_error[1][0],
            (unsigned long)imu_diag_arranque.probe_error[1][1],
            (unsigned long)imu_diag_arranque.probe_error[1][2],
            (unsigned long)imu_diag_arranque.probe_duracion_ms[0][0],
            (unsigned long)imu_diag_arranque.probe_duracion_ms[0][1],
            (unsigned long)imu_diag_arranque.probe_duracion_ms[0][2],
            (unsigned long)imu_diag_arranque.probe_duracion_ms[1][0],
            (unsigned long)imu_diag_arranque.probe_duracion_ms[1][1],
            (unsigned long)imu_diag_arranque.probe_duracion_ms[1][2]);
        if ((len > 0) && ((size_t)len < sizeof(texto)))
        {
            uartx_write_text(&huart6, texto);
        }

        /* USV 14.9: tiempos de arranque IMU, leidos desde RAM. */
        len = snprintf(
            texto, sizeof(texto),
            ">imu_149_espera_config_ms:%lu\r\n"
            ">imu_149_tick_antes_espera:%lu\r\n"
            ">imu_149_tick_inicio:%lu\r\n"
            ">imu_149_tick_fin:%lu\r\n"
            ">imu_149_espera_real_ms:%lu\r\n"
            ">imu_149_init_duracion_ms:%lu\r\n",
            (unsigned long)IMU_149_ESPERA_MS,
            (unsigned long)imu_149_tick_antes_espera,
            (unsigned long)imu_149_tick_inicio,
            (unsigned long)imu_149_tick_fin,
            (unsigned long)imu_149_espera_real_ms,
            (unsigned long)imu_149_init_duracion_ms);
        if ((len > 0) && ((size_t)len < sizeof(texto)))
        {
            uartx_write_text(&huart6, texto);
        }

        /* USV 15.0: instantaneas tomadas antes de que HAL limpie NACKF. */
        len = snprintf(
            texto, sizeof(texto),
            ">imu_150_pe:%lu\r\n"
            ">imu_150_bus_seguro:%u\r\n"
            ">imu_150_4a_estado:%u\r\n"
            ">imu_150_4a_eventos:%lu\r\n"
            ">imu_150_4a_isr_fin:%lu\r\n"
            ">imu_150_4a_tiempo_ms:%lu\r\n"
            ">imu_150_4b_estado:%u\r\n"
            ">imu_150_4b_eventos:%lu\r\n"
            ">imu_150_4b_isr_fin:%lu\r\n"
            ">imu_150_4b_tiempo_ms:%lu\r\n",
            (unsigned long)imu_150_pe_inicial,
            (unsigned int)imu_150_bus_seguro,
            (unsigned int)imu_150_4a.estado,
            (unsigned long)imu_150_4a.isr_eventos,
            (unsigned long)imu_150_4a.isr_fin,
            (unsigned long)imu_150_4a.duracion_ms,
            (unsigned int)imu_150_4b.estado,
            (unsigned long)imu_150_4b.isr_eventos,
            (unsigned long)imu_150_4b.isr_fin,
            (unsigned long)imu_150_4b.duracion_ms);
        if ((len > 0) && ((size_t)len < sizeof(texto)))
        {
            uartx_write_text(&huart6, texto);
        }

        /* USV 15.1: registros GPIOB capturados antes de probar la IMU. */
        len = snprintf(
            texto, sizeof(texto),
            ">imu_151_tick_ms:%lu\r\n"
            ">imu_151_moder:%lu\r\n"
            ">imu_151_otyper:%lu\r\n"
            ">imu_151_ospeedr:%lu\r\n"
            ">imu_151_pupdr:%lu\r\n"
            ">imu_151_afrl:%lu\r\n"
            ">imu_151_idr:%lu\r\n",
            (unsigned long)imu_151_gpio.tick_ms,
            (unsigned long)imu_151_gpio.moder,
            (unsigned long)imu_151_gpio.otyper,
            (unsigned long)imu_151_gpio.ospeedr,
            (unsigned long)imu_151_gpio.pupdr,
            (unsigned long)imu_151_gpio.afrl,
            (unsigned long)imu_151_gpio.idr);
        if ((len > 0) && ((size_t)len < sizeof(texto)))
        {
            uartx_write_text(&huart6, texto);
        }

        /* Interpretacion individual de los pines PB6 / PB7 desde RAM:
         * MODER=2 (alternativa), OTYPER=1 (open drain),
         * PUPDR=1 (pull up), AFRL=4 (I2C1).
         * LEVEL 1=alto en la instantanea, no demuestra ACK.
         */
        len = snprintf(
            texto, sizeof(texto),
            ">imu_151_pb6_mode:%lu\r\n"
            ">imu_151_pb7_mode:%lu\r\n"
            ">imu_151_pb6_od:%lu\r\n"
            ">imu_151_pb7_od:%lu\r\n"
            ">imu_151_pb6_pull:%lu\r\n"
            ">imu_151_pb7_pull:%lu\r\n"
            ">imu_151_pb6_af:%lu\r\n"
            ">imu_151_pb7_af:%lu\r\n"
            ">imu_151_pb6_level:%lu\r\n"
            ">imu_151_pb7_level:%lu\r\n",
            (unsigned long)((imu_151_gpio.moder >> 12U) & 0x3U),
            (unsigned long)((imu_151_gpio.moder >> 14U) & 0x3U),
            (unsigned long)((imu_151_gpio.otyper >> 6U) & 0x1U),
            (unsigned long)((imu_151_gpio.otyper >> 7U) & 0x1U),
            (unsigned long)((imu_151_gpio.pupdr >> 12U) & 0x3U),
            (unsigned long)((imu_151_gpio.pupdr >> 14U) & 0x3U),
            (unsigned long)((imu_151_gpio.afrl >> 24U) & 0xFU),
            (unsigned long)((imu_151_gpio.afrl >> 28U) & 0xFU),
            (unsigned long)((imu_151_gpio.idr >> 6U) & 0x1U),
            (unsigned long)((imu_151_gpio.idr >> 7U) & 0x1U));
        if ((len > 0) && ((size_t)len < sizeof(texto)))
        {
            uartx_write_text(&huart6, texto);
        }

        /* USV 15.2: reloj y temporizacion efectivos, sin sondeos extra. */
        len = snprintf(
            texto, sizeof(texto),
            ">imu_152_pclk1_hz:%lu\r\n"
            ">imu_152_timingr:%lu\r\n"
            ">imu_152_timing_ok:%u\r\n"
            ">imu_152_pclk_ok:%u\r\n",
            (unsigned long)imu_152_pclk1_hz,
            (unsigned long)imu_152_timingr,
            (unsigned int)(imu_152_timingr == USV_I2C1_TIMING_100KHZ),
            (unsigned int)(imu_152_pclk1_hz == 64000000U));
        if ((len > 0) && ((size_t)len < sizeof(texto)))
        {
            uartx_write_text(&huart6, texto);
        }

        /* USV 15.4: publica resultado del escaneo desde RAM, a 2 Hz.
         * estado=2 y consultadas=112 prueban que el barrido fue completo.
         * Las mascaras contienen todos los ACK; no se omiten dispositivos.
         */
        len = snprintf(
            texto, sizeof(texto),
            ">i2c_scan_estado:%u\r\n"
            ">i2c_scan_completo:%u\r\n"
            ">i2c_scan_consultadas:%u\r\n"
            ">i2c_scan_total:%u\r\n"
            ">i2c_scan_ultimo_addr:%u\r\n"
            ">i2c_scan_encontrados:%u\r\n"
            ">i2c_scan_hal_error:%u\r\n"
            ">i2c_scan_hal_timeout:%u\r\n"
            ">i2c_scan_hal_busy:%u\r\n"
            ">i2c_scan_error_bus:%u\r\n"
            ">i2c_scan_4a_hal:%u\r\n"
            ">i2c_scan_4a_error:%lu\r\n"
            ">i2c_scan_4b_hal:%u\r\n"
            ">i2c_scan_4b_error:%lu\r\n"
            ">i2c_scan_pclk1_hz:%lu\r\n"
            ">i2c_scan_timingr:%lu\r\n"
            ">i2c_scan_duracion_ms:%lu\r\n",
            (unsigned int)i2c_scan_154.estado,
            (unsigned int)(i2c_scan_154.estado == 2U),
            (unsigned int)i2c_scan_154.consultadas,
            (unsigned int)USV_I2C_SCAN_TOTAL,
            (unsigned int)i2c_scan_154.ultimo_addr,
            (unsigned int)i2c_scan_154.total_ack,
            (unsigned int)i2c_scan_154.hal_error,
            (unsigned int)i2c_scan_154.hal_timeout,
            (unsigned int)i2c_scan_154.hal_busy,
            (unsigned int)i2c_scan_154.error_bus,
            (unsigned int)i2c_scan_154.hal_4a,
            (unsigned long)i2c_scan_154.err_4a,
            (unsigned int)i2c_scan_154.hal_4b,
            (unsigned long)i2c_scan_154.err_4b,
            (unsigned long)i2c_scan_154.pclk1_hz,
            (unsigned long)i2c_scan_154.timingr,
            (unsigned long)i2c_scan_154.duracion_ms);
        if ((len > 0) && ((size_t)len < sizeof(texto)))
        {
            uartx_write_text(&huart6, texto);
        }
        /* Lista explicita de TODOS los ACK, hasta 16 por ciclo Teleplot.
         * Si hay mas, se rotan los restantes entre ciclos.
         * El nombre incluye la direccion hexadecimal: i2c_ack_4A=1.
         */
        if (i2c_scan_154.total_ack > 0U)
        {
            uint8_t n;
            for (n = 0U; n < 16U && n < i2c_scan_154.total_ack; ++n)
            {
                uint8_t addr_encontrada =
                    i2c_scan_154.ack_addr[i2c_scan_154_indice_publicar];
                len = snprintf(texto, sizeof(texto),
                    ">i2c_ack_%02X:1\r\n", (unsigned int)addr_encontrada);
                if ((len > 0) && ((size_t)len < sizeof(texto)))
                {
                    uartx_write_text(&huart6, texto);
                }
                i2c_scan_154_indice_publicar++;
                if (i2c_scan_154_indice_publicar >= i2c_scan_154.total_ack)
                {
                    i2c_scan_154_indice_publicar = 0U;
                }
            }
        }
        /* Mascaras de 32 direcciones: bit N = ACK en direccion N.
         * Permiten reconstruir el barrido completo sin enviar 112 etiquetas.
         */
        len = snprintf(
            texto, sizeof(texto),
            ">i2c_scan_mask_00_1f:%lu\r\n"
            ">i2c_scan_mask_20_3f:%lu\r\n"
            ">i2c_scan_mask_40_5f:%lu\r\n"
            ">i2c_scan_mask_60_7f:%lu\r\n",
            (unsigned long)i2c_scan_154.mascara_ack[0],
            (unsigned long)i2c_scan_154.mascara_ack[1],
            (unsigned long)i2c_scan_154.mascara_ack[2],
            (unsigned long)i2c_scan_154.mascara_ack[3]);
        if ((len > 0) && ((size_t)len < sizeof(texto)))
        {
            uartx_write_text(&huart6, texto);
        }

        /* Bloque 3: estado de recepcion GNSS. */
        len = snprintf(
            texto,
            sizeof(texto),
            ">gnss_rx_eventos:%lu\r\n"
            ">gnss_rx_bytes:%u\r\n"
            ">gps_rmc_ok:%u\r\n"
            ">gps_gga_ok:%u\r\n"
            ">gps_fix:%d\r\n"
            ">gps_satelites:%d\r\n"
            ">gps_hdop:%.2f\r\n",
            (unsigned long)gnss_rx_eventos,
            (unsigned int)GNSS_UARTRX.num_datos,
            (unsigned int)gps_rmc_ok,
            (unsigned int)gps_gga_ok,
            (int)gps_modo,
            (int)gps_satelites,
            gps_hor_dilu);

        if ((len > 0) && ((size_t)len < sizeof(texto)))
        {
            uartx_write_text(&huart6, texto);
        }

        /* Bloque 4: datos de navegacion GNSS. */
        len = snprintf(
            texto,
            sizeof(texto),
            ">gps_latitud:%.6f\r\n"
            ">gps_longitud:%.6f\r\n"
            ">gps_altitud_m:%.2f\r\n"
            ">gps_velocidad_kph:%.2f\r\n"
            ">gps_rumbo:%.2f\r\n",
            latitud,
            longitud,
            gps_altura,
            gps_vel_kph,
            gps_rumbo);

        if ((len > 0) && ((size_t)len < sizeof(texto)))
        {
            uartx_write_text(&huart6, texto);
        }

        /* Bloque 5: sensor de corriente LEM por PA0 / ADC1_INP0. */
        len = snprintf(
            texto,
            sizeof(texto),
            ">corriente_adc:%u\r\n"
            ">corriente_voltaje_v:%.3f\r\n"
            ">corriente_a:%.2f\r\n",
            (unsigned int)corriente_adc_raw,
            corriente_voltaje_v,
            corriente_lem_a);

        if ((len > 0) && ((size_t)len < sizeof(texto)))
        {
            uartx_write_text(&huart6, texto);
        }

        /* Bloque 6: voltaje de bateria por PC1 / ADC1_INP11. */
        len = snprintf(
            texto,
            sizeof(texto),
            ">bateria_adc:%u\r\n"
            ">bateria_adc_v:%.3f\r\n"
            ">bateria_voltaje_v:%.2f\r\n",
            (unsigned int)bateria_adc_raw,
            bateria_adc_v,
            bateria_voltaje_v);

        if ((len > 0) && ((size_t)len < sizeof(texto)))
        {
            uartx_write_text(&huart6, texto);
        }

        /* 14.1: indicadores locales de envio PUSVD por USART1/XBee.
         * tramas_enviadas solo confirma HAL_OK en UART, no recepcion RF. */
        len = snprintf(
            texto,
            sizeof(texto),
            ">pusvd_tx_uart_ok:%lu\r\n"
            ">pusvd_tx_uart_err:%lu\r\n"
            ">pusvd_tx_formato_err:%lu\r\n"
            ">pusvd_tx_ultimo_bytes:%u\r\n",
            (unsigned long)TELEMETRIA1.tramas_enviadas,
            (unsigned long)TELEMETRIA1.errores_uart,
            (unsigned long)TELEMETRIA1.errores_construccion,
            (unsigned int)TELEMETRIA1.longitud_tx);
        if ((len > 0) && ((size_t)len < sizeof(texto)))
        {
            uartx_write_text(&huart6, texto);
        }

        /* Diagnostico local: HAL_OK no implica entrega por RF. */
        len = snprintf(
            texto, sizeof(texto),
            ">xbee_rx_eventos:%lu\r\n"
            ">xbee_rx_bytes:%lu\r\n"
            ">xbee_rx_silencio_ms:%lu\r\n"
            ">xbee_rx_rearmes_ok:%lu\r\n"
            ">xbee_rx_rearmes_error:%lu\r\n"
            ">xbee_rx_watchdog:%lu\r\n"
            ">xbee_uart1_error_irq:%lu\r\n"
            ">xbee_uart1_error_codigo:%lu\r\n"
            ">xbee_rx_descartadas:%lu\r\n",
            (unsigned long)xbee_rx_eventos,
            (unsigned long)xbee_rx_bytes,
            (unsigned long)((uint32_t)(HAL_GetTick() - xbee_rx_ultimo_evento_ms)),
            (unsigned long)xbee_rx_rearmes_ok,
            (unsigned long)xbee_rx_rearmes_error,
            (unsigned long)xbee_rx_watchdog,
            (unsigned long)usv_xbee_uart1_error_irq,
            (unsigned long)usv_xbee_uart1_error_codigo,
            (unsigned long)xbee_tramas_descartadas);
        if ((len > 0) && ((size_t)len < sizeof(texto)))
        {
            uartx_write_text(&huart6, texto);
        }
#if PCB_BANCO_ACTIVO
        len = snprintf(texto, sizeof(texto),
            ">pcb_armado:%u\r\n>pcb_motor_pulso:%u\r\n"
            ">pcb_bomba_pulso:%u\r\n>pcb_do_pulso:%u\r\n"
            ">di1:%u\r\n>di2:%u\r\n>di3:%u\r\n>di4:%u\r\n"
            ">humedad_do:%u\r\n",
            (unsigned int)PCB_Banco_Armado(),
            (unsigned int)PCB_Banco_MotorActivo(),
            (unsigned int)PCB_Banco_BombaActiva(),
            (unsigned int)PCB_Banco_SalidaActiva(),
            (unsigned int)HAL_GPIO_ReadPin(DI1_PA4_GPIO_Port, DI1_PA4_Pin),
            (unsigned int)HAL_GPIO_ReadPin(DI2_PA5_GPIO_Port, DI2_PA5_Pin),
            (unsigned int)HAL_GPIO_ReadPin(DI3_PA6_GPIO_Port, DI3_PA6_Pin),
            (unsigned int)HAL_GPIO_ReadPin(DI4_PA7_GPIO_Port, DI4_PA7_Pin),
            (unsigned int)HAL_GPIO_ReadPin(HUMIDITY_DO_GPIO_Port, HUMIDITY_DO_Pin));
        if ((len > 0) && ((size_t)len < sizeof(texto)))
            uartx_write_text(&huart6, texto);
#endif
    }

    /* Envío a Teleplot cada 200 ms */
    /* if ((HAL_GetTick() - teleplot_last_ms) >= 200U)
    {
        teleplot_last_ms = HAL_GetTick();

        int len = snprintf(
            teleplot_tx,
            sizeof(teleplot_tx),
            ">imu_ok:%u\r\n"
            ">imu_addr:%u\r\n"
            ">imu_data_ok:%u\r\n"
            ">roll:%.2f\r\n"
            ">pitch:%.2f\r\n"
            ">yaw:%.2f\r\n"
            ">rx_eventos:%lu\r\n"
            ">tramas_validas:%lu\r\n"
            ">camara_rx:%d\r\n"
            ">servo_ccr3:%lu\r\n"
            ">pb2_estado:%u\r\n"
            ">enlace_tierra:%u\r\n",
            (unsigned int)imu_ok,
            (unsigned int)imu_addr,
            (unsigned int)imu_data_ok,
            imu_roll,
            imu_pitch,
            imu_yaw,
            (unsigned long)usv_rx_eventos,
            (unsigned long)usv_tramas_validas,
            (int)usv_camara_recibida,
            (unsigned long)TIM3->CCR3,
            (unsigned int)HAL_GPIO_ReadPin(
                LED_RX_TIERRA_GPIO_Port,
                LED_RX_TIERRA_Pin),
            (unsigned int)led_rx_activo);

        if (len > 0)
        {
            HAL_UART_Transmit(
                &huart6,
                (uint8_t *)teleplot_tx,
                (uint16_t)len,
                100U);
        }
    } */

    /*
     * PRUEBA 12.0 - CONTROL REAL DESDE $PUSVU:
     *
     * Una trama valida actualiza inmediatamente:
     * - servo PB0 / TIM3_CH3;
     * - motor babor PB4 / TIM3_CH1;
     * - motor estribor PB1 / TIM3_CH4.
     *
     * Los motores usan el rango completo -100..+100 %.
     * parada=1 mantiene ambos ESC en NEUTRO.
     */
    if (GPS_UARTRX.flag_rx == 1)
    {
        uint32_t ahora_rx = HAL_GetTick();

        xbee_rx_ultimo_evento_ms = ahora_rx;
        xbee_rx_eventos++;
        led_rx_ultimo_evento_ms = ahora_rx;
        led_rx_activo = 1U;

        uint16_t n_xbee = GPS_UARTRX.num_datos;
        xbee_rx_bytes += (uint32_t)n_xbee;
        uint8_t copia = (uint8_t)((GPS_UARTRX.trama_rx != NULL) &&
                                  (n_xbee > 0U) &&
                                  (n_xbee <= sizeof(xbee_fragmento_rx)));
        uint8_t linea_completa = 0U;
        if (copia != 0U)
            memcpy(xbee_fragmento_rx, GPS_UARTRX.trama_rx, n_xbee);
        else
            ++xbee_tramas_descartadas;
        /* Si HAL rechaza el rearme, watchdog reintentara desde main. */
        if (uartRX_DMA_Re_init(&GPS_UARTRX) == HAL_OK)
        {
            xbee_rx_rearmes_ok++;
            usv_xbee_uart1_recuperar = 0U;
        }
        else
        {
            xbee_rx_rearmes_error++;
            usv_xbee_uart1_recuperar = 1U;
        }
        comando_tierra_valido = copia
            ? XBee_ExtraerComandos(xbee_fragmento_rx, n_xbee,
                                    &comando_tierra, &linea_completa)
            : 0U;
        pusvu_diag_ultimo_valido = comando_tierra_valido;
        if (linea_completa != 0U)
            pusvu_diag_pendiente = 1U;

        if (comando_tierra_valido != 0U)
        {
            cmd_babor_rx_pct =
                USV_ComandoMotorFirmado(
                    comando_tierra.potencia_babor,
                    comando_tierra.babor_avante,
                    comando_tierra.babor_atras);

            cmd_estribor_rx_pct =
                USV_ComandoMotorFirmado(
                    comando_tierra.potencia_estribor,
                    comando_tierra.estribor_avante,
                    comando_tierra.estribor_atras);

            cmd_camara_rx_deg = comando_tierra.camara;
            parada_rx = comando_tierra.parada;

            comando_tierra_ultimo_valido_ms = ahora_rx;
            enlace_tierra_ok = 1U;
            failsafe_tierra_activo = 0U;
            pusvu_rx_validas++;
            /* Responder una sola vez por lote de comandos completos validos. */
            xbee_reply_pendiente = 1U;
            xbee_reply_deadline_ms = ahora_rx + XBEE_REPLY_GUARD_MS;

#if !PCB_BANCO_ACTIVO
            /* La camara sigue directamente el comando -90..+90 grados. */
            servo_test_angulo = (float)cmd_camara_rx_deg;
            SERVO_ANG(&SERVO1, servo_test_angulo);

            if ((parada_rx != 0U) || (motores_pwm_activos == 0U))
            {
                motor_babor_aplicado_pct = 0;
                motor_estribor_aplicado_pct = 0;
                motor_babor_pwm_us = PWM_NEUTRO;
                motor_estribor_pwm_us = PWM_NEUTRO;
            }
            else
            {
                motor_babor_pwm_us =
                    USV_MotorPctAPwmPrueba(
                        cmd_babor_rx_pct,
                        &motor_babor_aplicado_pct);

                motor_estribor_pwm_us =
                    USV_MotorPctAPwmPrueba(
                        cmd_estribor_rx_pct,
                        &motor_estribor_aplicado_pct);
            }

            if (motores_pwm_activos != 0U)
            {
                USV_Motor_Set(
                    &htim3,
                    TIM_CHANNEL_1,
                    motor_babor_pwm_us);

                USV_Motor_Set(
                    &htim3,
                    TIM_CHANNEL_4,
                    motor_estribor_pwm_us);
            }

            /* Relé de achique PB5 es activo en LOW; parada=1 siempre OFF.
             * En el arranque permanece OFF hasta la primera orden valida. */
            bomba_test_estado =
                (uint8_t)((comando_tierra.bomba != 0U) &&
                          (parada_rx == 0U));
            HAL_GPIO_WritePin(ACHIQUE_CTRL_GPIO_Port, ACHIQUE_CTRL_Pin,
                (bomba_test_estado != 0U) ? GPIO_PIN_RESET : GPIO_PIN_SET);
#endif
        }

    }

    /*
     * FAILSAFE DE ENLACE:
     * Si pasan mas de 500 ms sin una $PUSVU valida, ambos motores vuelven
     * a NEUTRO. El servo conserva la ultima posicion recibida.
     */
#if !PCB_BANCO_ACTIVO
    if ((enlace_tierra_ok != 0U) &&
        ((uint32_t)(HAL_GetTick() - comando_tierra_ultimo_valido_ms) >
         USV_FAILSAFE_TIERRA_MS))
    {
        enlace_tierra_ok = 0U;
        failsafe_tierra_activo = 1U;
        /* Parada de bomba ante perdida de enlace (rele activo en LOW). */
        bomba_test_estado = 0U;
        HAL_GPIO_WritePin(
            ACHIQUE_CTRL_GPIO_Port, ACHIQUE_CTRL_Pin, GPIO_PIN_SET);

        motor_babor_aplicado_pct = 0;
        motor_estribor_aplicado_pct = 0;
        motor_babor_pwm_us = PWM_NEUTRO;
        motor_estribor_pwm_us = PWM_NEUTRO;

        if (motores_pwm_activos != 0U)
        {
            USV_Motor_Set(
                &htim3,
                TIM_CHANNEL_1,
                motor_babor_pwm_us);

            USV_Motor_Set(
                &htim3,
                TIM_CHANNEL_4,
                motor_estribor_pwm_us);
        }
    }

#endif
    /*
     * Diagnostico $PUSVU por USART6 limitado a 500 ms.
     * Siempre muestra la ultima orden recibida.
     */
    if ((pusvu_diag_pendiente != 0U) &&
        ((uint32_t)(HAL_GetTick() - pusvu_diag_last_ms) >= 500U))
    {
        int len_rx;

        if (pusvu_diag_ultimo_valido != 0U)
        {
            int16_t babor_signed = 0;
            int16_t estribor_signed = 0;

            if (comando_tierra.babor_avante != 0U)
            {
                babor_signed =
                    (int16_t)comando_tierra.potencia_babor;
            }
            else if (comando_tierra.babor_atras != 0U)
            {
                babor_signed =
                    -(int16_t)comando_tierra.potencia_babor;
            }

            if (comando_tierra.estribor_avante != 0U)
            {
                estribor_signed =
                    (int16_t)comando_tierra.potencia_estribor;
            }
            else if (comando_tierra.estribor_atras != 0U)
            {
                estribor_signed =
                    -(int16_t)comando_tierra.potencia_estribor;
            }

            len_rx = snprintf(
                texto,
                sizeof(texto),
                "\r\n"
                "===== PUSVU DECODIFICADA =====\r\n"
                "PUSVU_OK          : 1\r\n"
                "Babor recibido    : %d %%\r\n"
                "Estribor recibido : %d %%\r\n"
                "Babor avante      : %u\r\n"
                "Babor atras       : %u\r\n"
                "Estribor avante   : %u\r\n"
                "Estribor atras    : %u\r\n"
                "Camara            : %d grados\r\n"
                "Bomba             : %u\r\n"
                "Parada emergencia : %u\r\n"
                "Babor aplicado    : %d %% / %u us\r\n"
                "Estribor aplicado : %d %% / %u us\r\n"
                "Failsafe enlace   : %u\r\n"
                "==============================\r\n",
                (int)babor_signed,
                (int)estribor_signed,
                (unsigned int)comando_tierra.babor_avante,
                (unsigned int)comando_tierra.babor_atras,
                (unsigned int)comando_tierra.estribor_avante,
                (unsigned int)comando_tierra.estribor_atras,
                (int)comando_tierra.camara,
                (unsigned int)comando_tierra.bomba,
                (unsigned int)comando_tierra.parada,
                (int)motor_babor_aplicado_pct,
                (unsigned int)motor_babor_pwm_us,
                (int)motor_estribor_aplicado_pct,
                (unsigned int)motor_estribor_pwm_us,
                (unsigned int)failsafe_tierra_activo);
        }
        else
        {
            len_rx = snprintf(
                texto,
                sizeof(texto),
                "\r\n"
                "===== PUSVU INVALIDA =====\r\n"
                "PUSVU_OK : 0\r\n"
                "==========================\r\n");
        }

        if ((len_rx > 0) && ((size_t)len_rx < sizeof(texto)))
        {
            uartx_write_text(&huart6, texto);
        }

        pusvu_diag_last_ms = HAL_GetTick();
        pusvu_diag_pendiente = 0U;
    }

    /*
     * GPS L76K / USART2:
     * La libreria gps.c busca RMC y GGA dentro del buffer NMEA recibido.
     * Los indicadores gps_rmc_ok / gps_gga_ok quedan enclavados cuando
     * se obtiene por primera vez una sentencia valida con solucion.
     */
    if (GNSS_UARTRX.flag_rx == 1)
    {
        uint8_t rmc_ok;
        uint8_t gga_ok;

        gnss_rx_eventos++;

        rmc_ok = GPS_RMC();
        gga_ok = GPS_GGA();

        if (rmc_ok != 0U)
        {
            gps_rmc_ok = 1U;
        }

        if (gga_ok != 0U)
        {
            gps_gga_ok = 1U;
        }
        if ((rmc_ok != 0U) || (gga_ok != 0U))
        {
            gnss_ultimo_fix_ms = HAL_GetTick();
            USV_ActualizarTelemetriaGNSS(1U);
        }
        uartRX_DMA_Re_init(&GNSS_UARTRX);
    }

    /* Un fix antiguo no puede seguir declarándose válido indefinidamente. */
    if ((uint32_t)(HAL_GetTick() - gnss_ultimo_fix_ms) > 3000U)
        TELEMETRIA1.datos.calidad_gps = 0U;

    /*
     * PRUEBA SOLICITADA POR EL PROFESOR:
     * PB2 parpadea aproximadamente a 2 Hz mientras se siguen recibiendo
     * tramas desde la estacion de tierra.
     */
    if (led_rx_activo != 0U)
    {
        uint32_t ahora_led = HAL_GetTick();

        if ((uint32_t)(ahora_led - led_rx_ultimo_evento_ms) > 400U)
        {
            /* No han llegado tramas recientemente: detiene el parpadeo. */
            led_rx_activo = 0U;
            HAL_GPIO_WritePin(
                LED_RX_TIERRA_GPIO_Port,
                LED_RX_TIERRA_Pin,
                GPIO_PIN_RESET);
        }
        else if ((uint32_t)(ahora_led - led_rx_ultimo_toggle_ms) >= 250U)
        {
            led_rx_ultimo_toggle_ms = ahora_led;

            HAL_GPIO_TogglePin(
                LED_RX_TIERRA_GPIO_Port,
                LED_RX_TIERRA_Pin);
        }
    }

    /* Rearme controlado de RX USART1 fuera de las interrupciones.
     * No toca PWM ni bomba: el failsafe permanece independiente. */
    {
        uint32_t ahora = HAL_GetTick();
        uint8_t sin_eventos =
            ((uint32_t)(ahora - xbee_rx_ultimo_evento_ms) >=
             XBEE_RX_REARME_SILENCIO_MS) ? 1U : 0U;
        if ((GPS_UARTRX.flag_rx == 0U) &&
            ((usv_xbee_uart1_recuperar != 0U) || (sin_eventos != 0U)) &&
            ((uint32_t)(ahora - xbee_rx_ultimo_rearme_ms) >=
             XBEE_RX_REARME_INTERVALO_MS))
        {
            HAL_StatusTypeDef estado;
            xbee_rx_ultimo_rearme_ms = ahora;
            xbee_rx_watchdog++;
            estado = HAL_UART_AbortReceive(&huart1);
            if (estado == HAL_OK)
            {
                estado = uartRX_DMA_Re_init(&GPS_UARTRX);
            }
            if (estado == HAL_OK)
            {
                xbee_rx_rearmes_ok++;
                usv_xbee_uart1_recuperar = 0U;
            }
            else
            {
                xbee_rx_rearmes_error++;
                usv_xbee_uart1_recuperar = 1U;
            }
        }
    }

    /* Half-duplex por RF: solo responder a un $PUSVU valido.
     * UART1 permanece con TX/RX separados: no usar HAL_HalfDuplex_Init. */
    if ((xbee_reply_pendiente != 0U) &&
        ((int32_t)(HAL_GetTick() - xbee_reply_deadline_ms) >= 0))
    {
        xbee_reply_pendiente = 0U;
        (void)TELEMETRIA_USV_Enviar(&TELEMETRIA1);
    }

    /* USER CODE END WHILE */

  }
}

void SystemClock_Config(void)
{
  RCC_OscInitTypeDef RCC_OscInitStruct = {0};
  RCC_ClkInitTypeDef RCC_ClkInitStruct = {0};

  /** Configure the main internal regulator output voltage
  */
  __HAL_PWR_VOLTAGESCALING_CONFIG(PWR_REGULATOR_VOLTAGE_SCALE3);

  while(!__HAL_PWR_GET_FLAG(PWR_FLAG_VOSRDY)) {}

  /** Initializes the RCC Oscillators according to the specified parameters
  * in the RCC_OscInitTypeDef structure.
  */
  RCC_OscInitStruct.OscillatorType = RCC_OSCILLATORTYPE_HSI;
  RCC_OscInitStruct.HSIState = RCC_HSI_ON;
  RCC_OscInitStruct.HSIDiv = RCC_HSI_DIV1;
  RCC_OscInitStruct.HSICalibrationValue = RCC_HSICALIBRATION_DEFAULT;
  RCC_OscInitStruct.PLL.PLLState = RCC_PLL_NONE;
  if (HAL_RCC_OscConfig(&RCC_OscInitStruct) != HAL_OK)
  {
    Error_Handler();
  }

  /** Initializes the CPU, AHB and APB buses clocks
  */
  RCC_ClkInitStruct.ClockType = RCC_CLOCKTYPE_HCLK|RCC_CLOCKTYPE_SYSCLK
                              |RCC_CLOCKTYPE_PCLK1|RCC_CLOCKTYPE_PCLK2
                              |RCC_CLOCKTYPE_PCLK3;
  RCC_ClkInitStruct.SYSCLKSource = RCC_SYSCLKSOURCE_HSI;
  RCC_ClkInitStruct.AHBCLKDivider = RCC_SYSCLK_DIV1;
  RCC_ClkInitStruct.APB1CLKDivider = RCC_HCLK_DIV1;
  RCC_ClkInitStruct.APB2CLKDivider = RCC_HCLK_DIV1;
  RCC_ClkInitStruct.APB3CLKDivider = RCC_HCLK_DIV1;

  if (HAL_RCC_ClockConfig(&RCC_ClkInitStruct, FLASH_LATENCY_3) != HAL_OK)
  {
    Error_Handler();
  }

  /** Configure the programming delay
  */
  __HAL_FLASH_SET_PROGRAM_DELAY(FLASH_PROGRAMMING_DELAY_1);
}

static void MX_ADC1_Init(void)
{

  ADC_ChannelConfTypeDef sConfig = {0};

  /** Common config
  */
  hadc1.Instance = ADC1;
  hadc1.Init.ClockPrescaler = ADC_CLOCK_ASYNC_DIV1;
  hadc1.Init.Resolution = ADC_RESOLUTION_12B;
  hadc1.Init.DataAlign = ADC_DATAALIGN_RIGHT;
  hadc1.Init.ScanConvMode = ADC_SCAN_ENABLE;
  hadc1.Init.EOCSelection = ADC_EOC_SINGLE_CONV;
  hadc1.Init.LowPowerAutoWait = DISABLE;
  hadc1.Init.ContinuousConvMode = ENABLE;
  hadc1.Init.NbrOfConversion = 3;
  hadc1.Init.DiscontinuousConvMode = DISABLE;
  hadc1.Init.ExternalTrigConv = ADC_SOFTWARE_START;
  hadc1.Init.ExternalTrigConvEdge = ADC_EXTERNALTRIGCONVEDGE_NONE;
  hadc1.Init.DMAContinuousRequests = ENABLE;
  hadc1.Init.SamplingMode = ADC_SAMPLING_MODE_NORMAL;
  hadc1.Init.Overrun = ADC_OVR_DATA_PRESERVED;
  hadc1.Init.OversamplingMode = DISABLE;
  if (HAL_ADC_Init(&hadc1) != HAL_OK)
  {
    Error_Handler();
  }

  /** Configure Regular Channel
  */
  sConfig.Channel = ADC_CHANNEL_0;
  sConfig.Rank = ADC_REGULAR_RANK_1;
  sConfig.SamplingTime = ADC_SAMPLETIME_47CYCLES_5;
  sConfig.SingleDiff = ADC_SINGLE_ENDED;
  sConfig.OffsetNumber = ADC_OFFSET_NONE;
  sConfig.Offset = 0;
  if (HAL_ADC_ConfigChannel(&hadc1, &sConfig) != HAL_OK)
  {
    Error_Handler();
  }

  /** Configure Regular Channel
  */
  sConfig.Channel = ADC_CHANNEL_11;
  sConfig.Rank = ADC_REGULAR_RANK_2;
  if (HAL_ADC_ConfigChannel(&hadc1, &sConfig) != HAL_OK)
  {
    Error_Handler();
  }

  /** Configure Regular Channel
  */
  sConfig.Channel = ADC_CHANNEL_13;
  sConfig.Rank = ADC_REGULAR_RANK_3;
  if (HAL_ADC_ConfigChannel(&hadc1, &sConfig) != HAL_OK)
  {
    Error_Handler();
  }

}

static void MX_GPDMA1_Init(void)
{

  /* Peripheral clock enable */
  __HAL_RCC_GPDMA1_CLK_ENABLE();

  /* GPDMA1 interrupt Init */
    HAL_NVIC_SetPriority(GPDMA1_Channel0_IRQn, 0, 0);
    HAL_NVIC_EnableIRQ(GPDMA1_Channel0_IRQn);
    HAL_NVIC_SetPriority(GPDMA1_Channel2_IRQn, 0, 0);
    HAL_NVIC_EnableIRQ(GPDMA1_Channel2_IRQn);

}

static void MX_I2C1_Init(void)
{

  hi2c1.Instance = I2C1;
  /* USV 15.2: solo cambiar TIMINGR I2C1 para velocidad estandar.
   * Referencia 15.1: 0x00602173 (Fast mode ~400 kHz).
   * 64 MHz de I2C1 (PCLK1), tr=300 ns, tf=100 ns,
   * filtro analogico activado y filtro digital en cero.
   * PRESC=3, SCLDEL=9, SDADEL=2, SCLH=0x40, SCLL=0x56.
   * Frecuencia teorica aproximada: 99.4 kHz (depende de tr/tf reales).
   */
  hi2c1.Init.Timing = USV_I2C1_TIMING_100KHZ;
  hi2c1.Init.OwnAddress1 = 0;
  hi2c1.Init.AddressingMode = I2C_ADDRESSINGMODE_7BIT;
  hi2c1.Init.DualAddressMode = I2C_DUALADDRESS_DISABLE;
  hi2c1.Init.OwnAddress2 = 0;
  hi2c1.Init.OwnAddress2Masks = I2C_OA2_NOMASK;
  hi2c1.Init.GeneralCallMode = I2C_GENERALCALL_DISABLE;
  hi2c1.Init.NoStretchMode = I2C_NOSTRETCH_DISABLE;
  if (HAL_I2C_Init(&hi2c1) != HAL_OK)
  {
    Error_Handler();
  }

  /** Configure Analogue filter
  */
  if (HAL_I2CEx_ConfigAnalogFilter(&hi2c1, I2C_ANALOGFILTER_ENABLE) != HAL_OK)
  {
    Error_Handler();
  }

  /** Configure Digital filter
  */
  if (HAL_I2CEx_ConfigDigitalFilter(&hi2c1, 0) != HAL_OK)
  {
    Error_Handler();
  }

}

static void MX_ICACHE_Init(void)
{

  /** Enable instruction cache in 1-way (direct mapped cache)
  */
  if (HAL_ICACHE_ConfigAssociativityMode(ICACHE_1WAY) != HAL_OK)
  {
    Error_Handler();
  }
  if (HAL_ICACHE_Enable() != HAL_OK)
  {
    Error_Handler();
  }

}

static void MX_TIM3_Init(void)
{

  TIM_ClockConfigTypeDef sClockSourceConfig = {0};
  TIM_MasterConfigTypeDef sMasterConfig = {0};
  TIM_OC_InitTypeDef sConfigOC = {0};

  htim3.Instance = TIM3;
  htim3.Init.Prescaler = 63;
  htim3.Init.CounterMode = TIM_COUNTERMODE_UP;
  htim3.Init.Period = 19999;
  htim3.Init.ClockDivision = TIM_CLOCKDIVISION_DIV1;
  htim3.Init.AutoReloadPreload = TIM_AUTORELOAD_PRELOAD_DISABLE;
  if (HAL_TIM_Base_Init(&htim3) != HAL_OK)
  {
    Error_Handler();
  }
  sClockSourceConfig.ClockSource = TIM_CLOCKSOURCE_INTERNAL;
  if (HAL_TIM_ConfigClockSource(&htim3, &sClockSourceConfig) != HAL_OK)
  {
    Error_Handler();
  }
  if (HAL_TIM_PWM_Init(&htim3) != HAL_OK)
  {
    Error_Handler();
  }
  sMasterConfig.MasterOutputTrigger = TIM_TRGO_RESET;
  sMasterConfig.MasterSlaveMode = TIM_MASTERSLAVEMODE_DISABLE;
  if (HAL_TIMEx_MasterConfigSynchronization(&htim3, &sMasterConfig) != HAL_OK)
  {
    Error_Handler();
  }
  sConfigOC.OCMode = TIM_OCMODE_PWM1;
  sConfigOC.Pulse = 0;
  sConfigOC.OCPolarity = TIM_OCPOLARITY_HIGH;
  sConfigOC.OCFastMode = TIM_OCFAST_DISABLE;
  if (HAL_TIM_PWM_ConfigChannel(&htim3, &sConfigOC, TIM_CHANNEL_1) != HAL_OK)
  {
    Error_Handler();
  }
  sConfigOC.Pulse = 1500;
  if (HAL_TIM_PWM_ConfigChannel(&htim3, &sConfigOC, TIM_CHANNEL_3) != HAL_OK)
  {
    Error_Handler();
  }
  sConfigOC.Pulse = 0;
  if (HAL_TIM_PWM_ConfigChannel(&htim3, &sConfigOC, TIM_CHANNEL_4) != HAL_OK)
  {
    Error_Handler();
  }
  HAL_TIM_MspPostInit(&htim3);

}

static void MX_USART1_UART_Init(void)
{

  huart1.Instance = USART1;
  huart1.Init.BaudRate = 115200;
  huart1.Init.WordLength = UART_WORDLENGTH_8B;
  huart1.Init.StopBits = UART_STOPBITS_1;
  huart1.Init.Parity = UART_PARITY_NONE;
  huart1.Init.Mode = UART_MODE_TX_RX;
  huart1.Init.HwFlowCtl = UART_HWCONTROL_NONE;
  huart1.Init.OverSampling = UART_OVERSAMPLING_16;
  huart1.Init.OneBitSampling = UART_ONE_BIT_SAMPLE_DISABLE;
  huart1.Init.ClockPrescaler = UART_PRESCALER_DIV1;
  huart1.AdvancedInit.AdvFeatureInit = UART_ADVFEATURE_NO_INIT;
  if (HAL_UART_Init(&huart1) != HAL_OK)
  {
    Error_Handler();
  }
  if (HAL_UARTEx_SetTxFifoThreshold(&huart1, UART_TXFIFO_THRESHOLD_1_8) != HAL_OK)
  {
    Error_Handler();
  }
  if (HAL_UARTEx_SetRxFifoThreshold(&huart1, UART_RXFIFO_THRESHOLD_1_8) != HAL_OK)
  {
    Error_Handler();
  }
  if (HAL_UARTEx_DisableFifoMode(&huart1) != HAL_OK)
  {
    Error_Handler();
  }

}

static void MX_USART2_UART_Init(void)
{

  huart2.Instance = USART2;
  huart2.Init.BaudRate = 9600;
  huart2.Init.WordLength = UART_WORDLENGTH_8B;
  huart2.Init.StopBits = UART_STOPBITS_1;
  huart2.Init.Parity = UART_PARITY_NONE;
  huart2.Init.Mode = UART_MODE_TX_RX;
  huart2.Init.HwFlowCtl = UART_HWCONTROL_NONE;
  huart2.Init.OverSampling = UART_OVERSAMPLING_16;
  huart2.Init.OneBitSampling = UART_ONE_BIT_SAMPLE_DISABLE;
  huart2.Init.ClockPrescaler = UART_PRESCALER_DIV1;
  huart2.AdvancedInit.AdvFeatureInit = UART_ADVFEATURE_NO_INIT;
  if (HAL_UART_Init(&huart2) != HAL_OK)
  {
    Error_Handler();
  }
  if (HAL_UARTEx_SetTxFifoThreshold(&huart2, UART_TXFIFO_THRESHOLD_1_8) != HAL_OK)
  {
    Error_Handler();
  }
  if (HAL_UARTEx_SetRxFifoThreshold(&huart2, UART_RXFIFO_THRESHOLD_1_8) != HAL_OK)
  {
    Error_Handler();
  }
  if (HAL_UARTEx_DisableFifoMode(&huart2) != HAL_OK)
  {
    Error_Handler();
  }

}

static void MX_USART3_UART_Init(void)
{

  huart3.Instance = USART3;
  huart3.Init.BaudRate = 115200;
  huart3.Init.WordLength = UART_WORDLENGTH_8B;
  huart3.Init.StopBits = UART_STOPBITS_1;
  huart3.Init.Parity = UART_PARITY_NONE;
  huart3.Init.Mode = UART_MODE_TX_RX;
  huart3.Init.HwFlowCtl = UART_HWCONTROL_NONE;
  huart3.Init.OverSampling = UART_OVERSAMPLING_16;
  huart3.Init.OneBitSampling = UART_ONE_BIT_SAMPLE_DISABLE;
  huart3.Init.ClockPrescaler = UART_PRESCALER_DIV1;
  huart3.AdvancedInit.AdvFeatureInit = UART_ADVFEATURE_NO_INIT;
  if (HAL_UART_Init(&huart3) != HAL_OK)
  {
    Error_Handler();
  }
  if (HAL_UARTEx_SetTxFifoThreshold(&huart3, UART_TXFIFO_THRESHOLD_1_8) != HAL_OK)
  {
    Error_Handler();
  }
  if (HAL_UARTEx_SetRxFifoThreshold(&huart3, UART_RXFIFO_THRESHOLD_1_8) != HAL_OK)
  {
    Error_Handler();
  }
  if (HAL_UARTEx_DisableFifoMode(&huart3) != HAL_OK)
  {
    Error_Handler();
  }

}

static void MX_USART6_UART_Init(void)
{

  huart6.Instance = USART6;
  huart6.Init.BaudRate = 115200;
  huart6.Init.WordLength = UART_WORDLENGTH_8B;
  huart6.Init.StopBits = UART_STOPBITS_1;
  huart6.Init.Parity = UART_PARITY_NONE;
  huart6.Init.Mode = UART_MODE_TX_RX;
  huart6.Init.HwFlowCtl = UART_HWCONTROL_NONE;
  huart6.Init.OverSampling = UART_OVERSAMPLING_16;
  huart6.Init.OneBitSampling = UART_ONE_BIT_SAMPLE_DISABLE;
  huart6.Init.ClockPrescaler = UART_PRESCALER_DIV1;
  huart6.AdvancedInit.AdvFeatureInit = UART_ADVFEATURE_NO_INIT;
  if (HAL_UART_Init(&huart6) != HAL_OK)
  {
    Error_Handler();
  }
  if (HAL_UARTEx_SetTxFifoThreshold(&huart6, UART_TXFIFO_THRESHOLD_1_8) != HAL_OK)
  {
    Error_Handler();
  }
  if (HAL_UARTEx_SetRxFifoThreshold(&huart6, UART_RXFIFO_THRESHOLD_1_8) != HAL_OK)
  {
    Error_Handler();
  }
  if (HAL_UARTEx_DisableFifoMode(&huart6) != HAL_OK)
  {
    Error_Handler();
  }

}

static void MX_GPIO_Init(void)
{
  GPIO_InitTypeDef GPIO_InitStruct = {0};

  /* GPIO Ports Clock Enable */
  __HAL_RCC_GPIOC_CLK_ENABLE();
  __HAL_RCC_GPIOA_CLK_ENABLE();
  __HAL_RCC_GPIOB_CLK_ENABLE();
  __HAL_RCC_GPIOD_CLK_ENABLE();

  /*Configure GPIO pin Output Level */
  HAL_GPIO_WritePin(TEMPE_GPIO_Port, TEMPE_Pin, GPIO_PIN_SET);

  /*Configure GPIO pin Output Level */
  HAL_GPIO_WritePin(GPIOB, LED_Pin|DO1_PB12_Pin|DO2_PB13_Pin|DO3_PB14_Pin
                          |DO4_PB15_Pin, GPIO_PIN_RESET);

  /* PB5 open-drain: SET = alta impedancia = rele desactivado. */
  HAL_GPIO_WritePin(
      ACHIQUE_CTRL_GPIO_Port,
      ACHIQUE_CTRL_Pin,
      GPIO_PIN_SET);

  /*Configure GPIO pin : TEMPE_Pin */
  GPIO_InitStruct.Pin = TEMPE_Pin;
  GPIO_InitStruct.Mode = GPIO_MODE_OUTPUT_OD;
  GPIO_InitStruct.Pull = GPIO_NOPULL;
  GPIO_InitStruct.Speed = GPIO_SPEED_FREQ_LOW;
  HAL_GPIO_Init(TEMPE_GPIO_Port, &GPIO_InitStruct);

  /*Configure GPIO pins : DI1_PA4_Pin DI2_PA5_Pin DI3_PA6_Pin DI4_PA7_Pin */
  GPIO_InitStruct.Pin = DI1_PA4_Pin|DI2_PA5_Pin|DI3_PA6_Pin|DI4_PA7_Pin;
  GPIO_InitStruct.Mode = GPIO_MODE_INPUT;
  GPIO_InitStruct.Pull = GPIO_NOPULL;
  HAL_GPIO_Init(GPIOA, &GPIO_InitStruct);

  /*Configure GPIO pin : HUMIDITY_DO_Pin */
  GPIO_InitStruct.Pin = HUMIDITY_DO_Pin;
  GPIO_InitStruct.Mode = GPIO_MODE_INPUT;
  GPIO_InitStruct.Pull = GPIO_NOPULL;
  HAL_GPIO_Init(HUMIDITY_DO_GPIO_Port, &GPIO_InitStruct);

  /*Configure GPIO pins : LED_Pin DO1_PB12_Pin DO2_PB13_Pin DO3_PB14_Pin
                           DO4_PB15_Pin */
  GPIO_InitStruct.Pin = LED_Pin|DO1_PB12_Pin|DO2_PB13_Pin|DO3_PB14_Pin
                          |DO4_PB15_Pin;
  GPIO_InitStruct.Mode = GPIO_MODE_OUTPUT_PP;
  GPIO_InitStruct.Pull = GPIO_NOPULL;
  GPIO_InitStruct.Speed = GPIO_SPEED_FREQ_LOW;
  HAL_GPIO_Init(GPIOB, &GPIO_InitStruct);

  /*Configure GPIO pin : PA13 */
  GPIO_InitStruct.Pin = GPIO_PIN_13;
  GPIO_InitStruct.Mode = GPIO_MODE_AF_PP;
  GPIO_InitStruct.Pull = GPIO_PULLUP;
  GPIO_InitStruct.Speed = GPIO_SPEED_FREQ_LOW;
  GPIO_InitStruct.Alternate = GPIO_AF0_TRACE;
  HAL_GPIO_Init(GPIOA, &GPIO_InitStruct);

  /*Configure GPIO pin : ACHIQUE_CTRL_Pin */
  GPIO_InitStruct.Pin = ACHIQUE_CTRL_Pin;
  GPIO_InitStruct.Mode = GPIO_MODE_OUTPUT_OD;
  GPIO_InitStruct.Pull = GPIO_NOPULL;
  GPIO_InitStruct.Speed = GPIO_SPEED_FREQ_LOW;
  HAL_GPIO_Init(ACHIQUE_CTRL_GPIO_Port, &GPIO_InitStruct);

  /* USER CODE BEGIN MX_GPIO_Init_2 */

  /*
   * PB2: LED de prueba del enlace ESTACION -> BOTE.
   * Se configura aqui para no depender de una regeneracion de CubeMX.
   */
  HAL_GPIO_WritePin(
      LED_RX_TIERRA_GPIO_Port,
      LED_RX_TIERRA_Pin,
      GPIO_PIN_RESET);

  GPIO_InitStruct.Pin = LED_RX_TIERRA_Pin;
  GPIO_InitStruct.Mode = GPIO_MODE_OUTPUT_PP;
  GPIO_InitStruct.Pull = GPIO_NOPULL;
  GPIO_InitStruct.Speed = GPIO_SPEED_FREQ_LOW;
  HAL_GPIO_Init(
      LED_RX_TIERRA_GPIO_Port,
      &GPIO_InitStruct);

  /* USER CODE END MX_GPIO_Init_2 */
}

 /* MPU Configuration */

void MPU_Config(void)
{
  MPU_Region_InitTypeDef MPU_InitStruct = {0};
  MPU_Attributes_InitTypeDef MPU_AttributesInit = {0};

  /* Disables the MPU */
  HAL_MPU_Disable();

  /** Initializes and configures the Region 0 and the memory to be protected
  */
  MPU_InitStruct.Enable = MPU_REGION_ENABLE;
  MPU_InitStruct.Number = MPU_REGION_NUMBER0;
  MPU_InitStruct.BaseAddress = 0x08FFF000;
  MPU_InitStruct.LimitAddress = 0x08FFFFFF;
  MPU_InitStruct.AttributesIndex = MPU_ATTRIBUTES_NUMBER0;
  MPU_InitStruct.AccessPermission = MPU_REGION_ALL_RO;
  MPU_InitStruct.DisableExec = MPU_INSTRUCTION_ACCESS_DISABLE;
  MPU_InitStruct.IsShareable = MPU_ACCESS_NOT_SHAREABLE;

  HAL_MPU_ConfigRegion(&MPU_InitStruct);

  /** Initializes and configures the Attribute 0 and the memory to be protected
  */
  MPU_AttributesInit.Number = MPU_ATTRIBUTES_NUMBER0;
  MPU_AttributesInit.Attributes = INNER_OUTER(MPU_NOT_CACHEABLE);

  HAL_MPU_ConfigMemoryAttributes(&MPU_AttributesInit);
  /* Enables the MPU */
  HAL_MPU_Enable(MPU_PRIVILEGED_DEFAULT);

}

void Error_Handler(void)
{
  __disable_irq();
  while (1)
  {
  }
}
